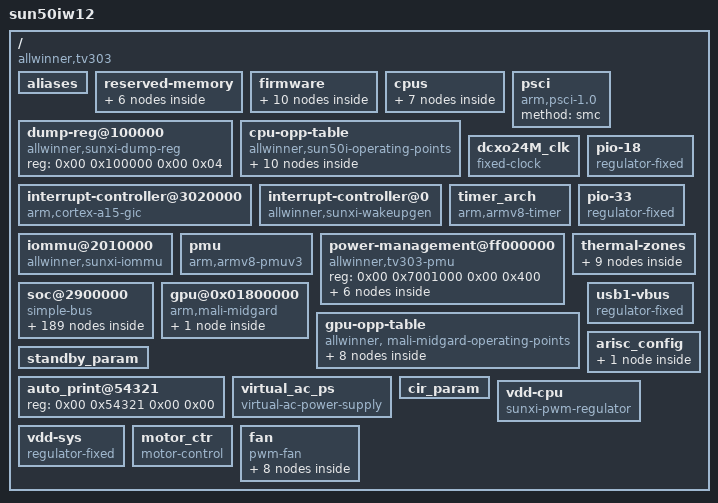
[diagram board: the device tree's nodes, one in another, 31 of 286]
/dts-v1/;

/ {
	interrupt-parent = <0x01>;
	#address-cells = <0x02>;
	#size-cells = <0x02>;
	model = "sun50iw12";
	compatible = "allwinner,tv303\0arm,sun50iw12p1";

	aliases {
		mmc0 = "/soc@2900000/sdmmc@4020000";
		mmc2 = "/soc@2900000/sdmmc@4022000";
		spi0 = "/soc@2900000/spi@4025000";
		spi1 = "/soc@2900000/spi@4026000";
		twi0 = "/soc@2900000/twi@2502000";
		twi1 = "/soc@2900000/twi@2502400";
		twi2 = "/soc@2900000/twi@2502800";
		twi3 = "/soc@2900000/twi@2502C00";
		twi4 = "/soc@2900000/r_twi@7081400";
		twi5 = "/soc@2900000/r_twi@7081800";
		nand0 = "/soc@2900000/nand0@04011000";
		global-timer0 = "/soc@2900000/timer@3060000";
		ir0 = "/soc@2900000/s_cir@7040000";
		ac200 = "/soc@2900000/ac200@0";
		pwm = "/soc@2900000/pwm@2000c00";
		pwm0 = "/soc@2900000/pwm0@2000c10";
		pwm1 = "/soc@2900000/pwm1@2000c11";
		pwm2 = "/soc@2900000/pwm2@2000c12";
		pwm3 = "/soc@2900000/pwm3@2000c13";
		pwm4 = "/soc@2900000/pwm4@2000c14";
		pwm5 = "/soc@2900000/pwm5@2000c15";
		pwm6 = "/soc@2900000/pwm6@2000c16";
		pwm7 = "/soc@2900000/pwm7@2000c17";
		s_pwm = "/soc@2900000/s_pwm@7020c00";
		s_pwm0 = "/soc@2900000/s_pwm0@7020c10";
		s_pwm1 = "/soc@2900000/s_pwm1@7020c11";
		s_pwm2 = "/soc@2900000/s_pwm2@7004012";
		ve0 = "/soc@2900000/ve@1c0e000";
		ve1 = "/soc@2900000/ve1@1c0e000";
		serial0 = "/soc@2900000/uart@2500000";
		serial1 = "/soc@2900000/uart@2500400";
		arisc_config = "/arisc_config";
		standby_param = "/standby_param";
		cir_param = "/cir_param";
	};

	reserved-memory {
		#address-cells = <0x02>;
		#size-cells = <0x02>;
		ranges;

		bl31 {
			reg = <0x00 0x48000000 0x00 0x180000>;
		};

		optee {
			reg = <0x00 0x48600000 0x00 0x100000>;
		};

		mipsloader {
			reg = <0x00 0x4b100000 0x00 0x2841000>;
			phandle = <0x5d>;
		};

		decd {
			reg = <0x00 0x4d941000 0x00 0x20000>;
			phandle = <0x5c>;
		};

		cpu_comm {
			reg = <0x00 0x4e300000 0x00 0x500000>;
			phandle = <0x62>;
		};

		framebuf {
			reg = <0x00 0x4bf41000 0x00 0x1a00000>;
			phandle = <0x63>;
		};
	};

	firmware {

		android {
			compatible = "android,firmware";
			boot_devices = "soc@2900000/4020000.sdmmc,soc@2900000/4022000.sdmmc,soc@2900000";

			vbmeta {
				compatible = "android,vbmeta";
				parts = "vbmeta,vbmeta_system,vbmeta_vendor,boot";
			};
		};

		optee {
			compatible = "linaro,optee-tz";
			method = "smc";
		};

		mips {

			mips_code {
				file_name = "display.bin";
				cert_name = "display.der";
				load_addr = <0x4b100000>;
			};

			mips_database {
				file_name = "database.TSE";
				cert_name = "database.der";
				load_addr = <0x4ba00000>;
			};

			mips_project_table {
				file_name = "projecttable.TSE";
				cert_name = "projecttable.der";
			};

			mips_db_project {
				file_name = "ProjectID_";
			};

			mips_xml {
				file_name = "mips.xml";
				load_addr = <0x4f308000>;
			};

			mips_memory {
				mips_only_size = <0x3200000>;
				shm_size = <0x1018000>;
			};
		};
	};

	cpus {
		#address-cells = <0x02>;
		#size-cells = <0x00>;

		cpu@0 {
			device_type = "cpu";
			compatible = "arm,cortex-a53\0arm,armv8";
			reg = <0x00 0x00>;
			enable-method = "psci";
			clocks = <0x02 0x13>;
			dynamic-power-coefficient = <0xf6>;
			cpu-idle-states = <0x03 0x04>;
			operating-points-v2 = <0x05>;
			#cooling-cells = <0x02>;
			cpu-supply = <0x06>;
			phandle = <0x09>;
		};

		cpu@1 {
			device_type = "cpu";
			compatible = "arm,cortex-a53\0arm,armv8";
			reg = <0x00 0x01>;
			enable-method = "psci";
			clocks = <0x02 0x13>;
			dynamic-power-coefficient = <0xf6>;
			cpu-idle-states = <0x03 0x04>;
			operating-points-v2 = <0x05>;
			#cooling-cells = <0x02>;
			phandle = <0x0a>;
		};

		cpu@2 {
			device_type = "cpu";
			compatible = "arm,cortex-a53\0arm,armv8";
			reg = <0x00 0x02>;
			enable-method = "psci";
			clocks = <0x02 0x13>;
			dynamic-power-coefficient = <0xf6>;
			cpu-idle-states = <0x03 0x04>;
			operating-points-v2 = <0x05>;
			#cooling-cells = <0x02>;
			phandle = <0x0b>;
		};

		cpu@3 {
			device_type = "cpu";
			compatible = "arm,cortex-a53\0arm,armv8";
			reg = <0x00 0x03>;
			enable-method = "psci";
			clocks = <0x02 0x13>;
			dynamic-power-coefficient = <0xf6>;
			cpu-idle-states = <0x03 0x04>;
			operating-points-v2 = <0x05>;
			#cooling-cells = <0x02>;
			phandle = <0x0c>;
		};

		idle-states {
			entry-method = "arm,psci";

			cpu-sleep-0 {
				compatible = "arm,idle-state";
				arm,psci-suspend-param = <0x10000>;
				entry-latency-us = <0x2e>;
				exit-latency-us = <0x3b>;
				min-residency-us = <0xdf2>;
				local-timer-stop;
				phandle = <0x03>;
			};

			cluster-sleep-0 {
				compatible = "arm,idle-state";
				arm,psci-suspend-param = <0x1010000>;
				entry-latency-us = <0x2f>;
				exit-latency-us = <0x4a>;
				min-residency-us = <0x1388>;
				local-timer-stop;
				phandle = <0x04>;
			};
		};
	};

	psci {
		compatible = "arm,psci-1.0";
		method = "smc";
	};

	dump-reg@100000 {
		compatible = "allwinner,sunxi-dump-reg";
		reg = <0x00 0x100000 0x00 0x04>;
		phandle = <0x64>;
	};

	cpu-opp-table {
		compatible = "allwinner,sun50i-operating-points";
		nvmem-cells = <0x07>;
		nvmem-cell-names = "speed";
		opp-shared;
		phandle = <0x05>;

		opp@672000000 {
			opp-hz = <0x00 0x280de800>;
			clock-latency-ns = <0x3b9b0>;
			opp-microvolt = <0xdbba0>;
			opp-microvolt-0x00010042 = <0xdbba0>;
			opp-microvolt-0x00020042 = <0xdbba0>;
			opp-microvolt-0x00040042 = <0xdbba0>;
			opp-microvolt-0x00090042 = <0xdbba0>;
			opp-microvolt-0x000a0042 = <0xdbba0>;
			opp-microvolt-0x000c0042 = <0xdbba0>;
			opp-microvolt-0x00010043 = <0xdbba0>;
			opp-microvolt-0x00020043 = <0xdbba0>;
			opp-microvolt-0x00040043 = <0xdbba0>;
			opp-microvolt-0x00090043 = <0xdbba0>;
			opp-microvolt-0x000a0043 = <0xdbba0>;
			opp-microvolt-0x000c0043 = <0xdbba0>;
			opp-microvolt-0x0002001f = <0xdbba0>;
			opp-microvolt-0x0002002f = <0xdbba0>;
			opp-microvolt-0x000a001f = <0xdbba0>;
			opp-microvolt-0x000a002f = <0xdbba0>;
			opp-microvolt-0x000a0040 = <0xdbba0>;
		};

		opp@792000000 {
			opp-hz = <0x00 0x2f34f600>;
			clock-latency-ns = <0x3b9b0>;
			opp-microvolt = <0xdbba0>;
			opp-microvolt-0x00010042 = <0xdbba0>;
			opp-microvolt-0x00020042 = <0xdbba0>;
			opp-microvolt-0x00040042 = <0xdbba0>;
			opp-microvolt-0x00090042 = <0xdbba0>;
			opp-microvolt-0x000a0042 = <0xdbba0>;
			opp-microvolt-0x000c0042 = <0xdbba0>;
			opp-microvolt-0x00010043 = <0xdbba0>;
			opp-microvolt-0x00020043 = <0xdbba0>;
			opp-microvolt-0x00040043 = <0xdbba0>;
			opp-microvolt-0x00090043 = <0xdbba0>;
			opp-microvolt-0x000a0043 = <0xdbba0>;
			opp-microvolt-0x000c0043 = <0xdbba0>;
			opp-microvolt-0x0002001f = <0xdbba0>;
			opp-microvolt-0x0002002f = <0xdbba0>;
			opp-microvolt-0x000a001f = <0xdbba0>;
			opp-microvolt-0x000a002f = <0xdbba0>;
			opp-microvolt-0x000a0040 = <0xdbba0>;
		};

		opp@1008000000 {
			opp-hz = <0x00 0x3c14dc00>;
			clock-latency-ns = <0x3b9b0>;
			opp-microvolt = <0xe57e0>;
			opp-microvolt-0x00010042 = <0xe57e0>;
			opp-microvolt-0x00020042 = <0xe57e0>;
			opp-microvolt-0x00040042 = <0xe57e0>;
			opp-microvolt-0x00090042 = <0xe57e0>;
			opp-microvolt-0x000a0042 = <0xdbba0>;
			opp-microvolt-0x000c0042 = <0xdbba0>;
			opp-microvolt-0x00010043 = <0xe57e0>;
			opp-microvolt-0x00020043 = <0xe57e0>;
			opp-microvolt-0x00040043 = <0xe57e0>;
			opp-microvolt-0x00090043 = <0xe57e0>;
			opp-microvolt-0x000a0043 = <0xdbba0>;
			opp-microvolt-0x000c0043 = <0xdbba0>;
			opp-microvolt-0x0002001f = <0xdbba0>;
			opp-microvolt-0x0002002f = <0xdbba0>;
			opp-microvolt-0x000a001f = <0xdbba0>;
			opp-microvolt-0x000a002f = <0xdbba0>;
			opp-microvolt-0x000a0040 = <0xdbba0>;
		};

		opp@1104000000 {
			opp-hz = <0x00 0x41cdb400>;
			clock-latency-ns = <0x3b9b0>;
			opp-microvolt = <0x00>;
			opp-microvolt-0x00010042 = <0xea600>;
			opp-microvolt-0x00020042 = <0xea600>;
			opp-microvolt-0x00040042 = <0xea600>;
			opp-microvolt-0x00090042 = <0xea600>;
			opp-microvolt-0x000a0042 = <0xe57e0>;
			opp-microvolt-0x000c0042 = <0xe57e0>;
			opp-microvolt-0x00010043 = <0xea600>;
			opp-microvolt-0x00020043 = <0xea600>;
			opp-microvolt-0x00040043 = <0xea600>;
			opp-microvolt-0x00090043 = <0xea600>;
			opp-microvolt-0x000a0043 = <0xe57e0>;
			opp-microvolt-0x000c0043 = <0xe57e0>;
			opp-microvolt-0x0002001f = <0xe57e0>;
			opp-microvolt-0x0002002f = <0xe57e0>;
			opp-microvolt-0x000a001f = <0xe57e0>;
			opp-microvolt-0x000a002f = <0xe57e0>;
			opp-microvolt-0x000a0040 = <0xe57e0>;
		};

		opp@1200000000 {
			opp-hz = <0x00 0x47868c00>;
			clock-latency-ns = <0x3b9b0>;
			opp-microvolt = <0xf4240>;
			opp-microvolt-0x00010042 = <0xf4240>;
			opp-microvolt-0x00020042 = <0xf4240>;
			opp-microvolt-0x00040042 = <0xf4240>;
			opp-microvolt-0x00090042 = <0xf4240>;
			opp-microvolt-0x000a0042 = <0xea600>;
			opp-microvolt-0x000c0042 = <0xe57e0>;
			opp-microvolt-0x00010043 = <0xf4240>;
			opp-microvolt-0x00020043 = <0xf4240>;
			opp-microvolt-0x00040043 = <0xf4240>;
			opp-microvolt-0x00090043 = <0xf4240>;
			opp-microvolt-0x000a0043 = <0xea600>;
			opp-microvolt-0x000c0043 = <0xe57e0>;
			opp-microvolt-0x0002001f = <0xea600>;
			opp-microvolt-0x0002002f = <0xea600>;
			opp-microvolt-0x000a001f = <0xea600>;
			opp-microvolt-0x000a002f = <0xea600>;
			opp-microvolt-0x000a0040 = <0xea600>;
		};

		opp@1296000000 {
			opp-hz = <0x00 0x4d3f6400>;
			clock-latency-ns = <0x3b9b0>;
			opp-microvolt = <0x102ca0>;
			opp-microvolt-0x00010042 = <0x00>;
			opp-microvolt-0x00020042 = <0x00>;
			opp-microvolt-0x00040042 = <0x00>;
			opp-microvolt-0x00090042 = <0x00>;
			opp-microvolt-0x000a0042 = <0x00>;
			opp-microvolt-0x000c0042 = <0x00>;
			opp-microvolt-0x00010043 = <0x00>;
			opp-microvolt-0x00020043 = <0x00>;
			opp-microvolt-0x00040043 = <0x00>;
			opp-microvolt-0x00090043 = <0x00>;
			opp-microvolt-0x000a0043 = <0x00>;
			opp-microvolt-0x000c0043 = <0x00>;
			opp-microvolt-0x0002001f = <0x00>;
			opp-microvolt-0x0002002f = <0x00>;
			opp-microvolt-0x000a001f = <0x00>;
			opp-microvolt-0x000a002f = <0x00>;
			opp-microvolt-0x000a0040 = <0x00>;
		};

		opp@1320000000 {
			opp-hz = <0x00 0x4ead9a00>;
			clock-latency-ns = <0x3b9b0>;
			opp-microvolt = <0x00>;
			opp-microvolt-0x00010042 = <0x10c8e0>;
			opp-microvolt-0x00020042 = <0x10c8e0>;
			opp-microvolt-0x00040042 = <0x10c8e0>;
			opp-microvolt-0x00090042 = <0x10c8e0>;
			opp-microvolt-0x000a0042 = <0xf4240>;
			opp-microvolt-0x000c0042 = <0xe57e0>;
			opp-microvolt-0x00010043 = <0x10c8e0>;
			opp-microvolt-0x00020043 = <0x10c8e0>;
			opp-microvolt-0x00040043 = <0x10c8e0>;
			opp-microvolt-0x00090043 = <0x10c8e0>;
			opp-microvolt-0x000a0043 = <0xf4240>;
			opp-microvolt-0x000c0043 = <0xe57e0>;
			opp-microvolt-0x0002001f = <0xf4240>;
			opp-microvolt-0x0002002f = <0xf4240>;
			opp-microvolt-0x000a001f = <0xf4240>;
			opp-microvolt-0x000a002f = <0xf4240>;
			opp-microvolt-0x000a0040 = <0xf4240>;
		};

		opp@1392000000 {
			opp-hz = <0x00 0x52f83c00>;
			clock-latency-ns = <0x3b9b0>;
			opp-microvolt = <0x10c8e0>;
			opp-microvolt-0x00010042 = <0x00>;
			opp-microvolt-0x00020042 = <0x00>;
			opp-microvolt-0x00040042 = <0x00>;
			opp-microvolt-0x00090042 = <0x00>;
			opp-microvolt-0x000a0042 = <0x00>;
			opp-microvolt-0x000c0042 = <0x00>;
			opp-microvolt-0x00010043 = <0x00>;
			opp-microvolt-0x00020043 = <0x00>;
			opp-microvolt-0x00040043 = <0x00>;
			opp-microvolt-0x00090043 = <0x00>;
			opp-microvolt-0x000a0043 = <0x00>;
			opp-microvolt-0x000c0043 = <0x00>;
			opp-microvolt-0x0002001f = <0x00>;
			opp-microvolt-0x0002002f = <0x00>;
			opp-microvolt-0x000a001f = <0x00>;
			opp-microvolt-0x000a002f = <0x00>;
			opp-microvolt-0x000a0040 = <0x00>;
		};

		opp@1416000000 {
			opp-hz = <0x00 0x54667200>;
			clock-latency-ns = <0x3b9b0>;
			opp-microvolt = <0x00>;
			opp-microvolt-0x00010042 = <0x00>;
			opp-microvolt-0x00020042 = <0x00>;
			opp-microvolt-0x00040042 = <0x00>;
			opp-microvolt-0x00090042 = <0x00>;
			opp-microvolt-0x000a0042 = <0x00>;
			opp-microvolt-0x000c0042 = <0x00>;
			opp-microvolt-0x00010043 = <0x00>;
			opp-microvolt-0x00020043 = <0x00>;
			opp-microvolt-0x00040043 = <0x00>;
			opp-microvolt-0x00090043 = <0x00>;
			opp-microvolt-0x000a0043 = <0x00>;
			opp-microvolt-0x000c0043 = <0x00>;
			opp-microvolt-0x0002001f = <0x102ca0>;
			opp-microvolt-0x0002002f = <0x102ca0>;
			opp-microvolt-0x000a001f = <0x102ca0>;
			opp-microvolt-0x000a002f = <0x102ca0>;
			opp-microvolt-0x000a0040 = <0x102ca0>;
		};

		opp@1512000000 {
			opp-hz = <0x00 0x5a1f4a00>;
			clock-latency-ns = <0x3b9b0>;
			opp-microvolt = <0x00>;
			opp-microvolt-0x00010042 = <0x00>;
			opp-microvolt-0x00020042 = <0x00>;
			opp-microvolt-0x00040042 = <0x00>;
			opp-microvolt-0x00090042 = <0x00>;
			opp-microvolt-0x000a0042 = <0x00>;
			opp-microvolt-0x000c0042 = <0x00>;
			opp-microvolt-0x00010043 = <0x00>;
			opp-microvolt-0x00020043 = <0x00>;
			opp-microvolt-0x00040043 = <0x00>;
			opp-microvolt-0x00090043 = <0x00>;
			opp-microvolt-0x000a0043 = <0x00>;
			opp-microvolt-0x000c0043 = <0x00>;
			opp-microvolt-0x0002001f = <0x10c8e0>;
			opp-microvolt-0x0002002f = <0x10c8e0>;
			opp-microvolt-0x000a001f = <0x10c8e0>;
			opp-microvolt-0x000a002f = <0x10c8e0>;
			opp-microvolt-0x000a0040 = <0x10c8e0>;
		};
	};

	dcxo24M_clk {
		#clock-cells = <0x00>;
		compatible = "fixed-clock";
		clock-frequency = <0x16e3600>;
		clock-output-names = "dcxo24M";
		phandle = <0x14>;
	};

	interrupt-controller@3020000 {
		compatible = "arm,cortex-a15-gic\0arm,cortex-a9-gic";
		#interrupt-cells = <0x03>;
		#address-cells = <0x00>;
		interrupt-controller;
		reg = <0x00 0x3021000 0x00 0x1000 0x00 0x3022000 0x00 0x2000 0x00 0x3024000 0x00 0x2000 0x00 0x3026000 0x00 0x2000>;
		interrupts = <0x01 0x09 0xf04>;
		interrupt-parent = <0x08>;
		phandle = <0x08>;
	};

	interrupt-controller@0 {
		compatible = "allwinner,sunxi-wakeupgen";
		interrupt-controller;
		#interrupt-cells = <0x03>;
		interrupt-parent = <0x08>;
		phandle = <0x01>;
	};

	timer_arch {
		compatible = "arm,armv8-timer";
		interrupts = <0x01 0x0d 0xf04 0x01 0x0e 0xf04 0x01 0x0b 0xf04 0x01 0x0a 0xf04>;
		clock-frequency = <0x16e3600>;
		interrupt-parent = <0x08>;
		arm,no-tick-in-suspend;
	};

	iommu@2010000 {
		compatible = "allwinner,sunxi-iommu";
		reg = <0x00 0x2010000 0x00 0x1000>;
		interrupts = <0x00 0x47 0x04>;
		interrupt-names = "iommu-irq";
		clocks = <0x02 0x30>;
		clock-names = "iommu";
		#iommu-cells = <0x02>;
		phandle = <0x11>;
	};

	pmu {
		compatible = "arm,armv8-pmuv3";
		interrupts = <0x00 0xac 0x04 0x00 0xad 0x04 0x00 0xae 0x04 0x00 0xaf 0x04>;
		interrupt-affinity = <0x09 0x0a 0x0b 0x0c>;
	};

	power-management@ff000000 {
		compatible = "allwinner,tv303-pmu\0syscon\0simple-mfd";
		reg = <0x00 0x7001000 0x00 0x400>;
		phandle = <0x65>;

		power-controller {
			compatible = "allwinner,tv303-power-controller";
			clocks = <0x0d 0x0f>;
			clock-names = "ppu";
			resets = <0x0d 0x06>;
			reset-names = "ppu_rst";
			#power-domain-cells = <0x01>;
			#address-cells = <0x01>;
			#size-cells = <0x00>;
			phandle = <0x12>;

			pd_gpu@0 {
				reg = <0x00>;
			};

			pd_tvfe@1 {
				reg = <0x01>;
			};

			pd_tvcap@2 {
				reg = <0x02>;
			};

			pd_ve@3 {
				reg = <0x03>;
			};

			pd_av1@4 {
				reg = <0x04>;
			};
		};
	};

	pio-18 {
		compatible = "regulator-fixed";
		regulator-name = "pio-18";
		regulator-min-microvolt = <0x1b7740>;
		regulator-max-microvolt = <0x1b7740>;
		phandle = <0x16>;
	};

	pio-33 {
		compatible = "regulator-fixed";
		regulator-name = "pio-33";
		regulator-min-microvolt = <0x325aa0>;
		regulator-max-microvolt = <0x325aa0>;
		phandle = <0x17>;
	};

	thermal-zones {

		cpu_thermal_zone {
			polling-delay-passive = <0x1f4>;
			polling-delay = <0x3e8>;
			thermal-sensors = <0x0e 0x01>;
			sustainable-power = <0x228>;

			trips {
				phandle = <0x66>;

				trip-point@0 {
					temperature = <0x13880>;
					type = "passive";
					hysteresis = <0x00>;
					phandle = <0x67>;
				};

				trip-point@1 {
					temperature = <0x19a28>;
					type = "passive";
					hysteresis = <0x00>;
					phandle = <0x0f>;
				};

				cpu_crit@0 {
					temperature = <0x1c138>;
					type = "critical";
					hysteresis = <0x00>;
					phandle = <0x68>;
				};
			};

			cooling-maps {

				map0 {
					trip = <0x0f>;
					cooling-device = <0x09 0xffffffff 0xffffffff>;
					contribution = <0x400>;
				};

				map1 {
					trip = <0x0f>;
					cooling-device = <0x10 0xffffffff 0xffffffff>;
					contribution = <0x400>;
				};
			};
		};

		gpu_thermal_zone {
			polling-delay-passive = <0x1f4>;
			polling-delay = <0x3e8>;
			thermal-sensors = <0x0e 0x00>;
			sustainable-power = <0x228>;
		};
	};

	soc@2900000 {
		compatible = "simple-bus";
		#address-cells = <0x02>;
		#size-cells = <0x02>;
		ranges;
		phandle = <0x69>;

		sram_ctrl@3000000 {
			compatible = "allwinner,sram_ctrl";
			reg = <0x00 0x3000000 0x00 0x16c>;
			phandle = <0x6a>;

			soc_ver {
				offset = <0x24>;
				mask = <0x07>;
				shift = <0x00>;
				ver_a = <0x18600000>;
			};

			soc_id {
				offset = <0x200>;
				mask = <0x01>;
				shift = <0x16>;
			};

			soc_bin {
				offset = <0x00>;
				mask = <0x3ff>;
				shift = <0x00>;
			};
		};

		av1@1c0d000 {
			compatible = "allwinner,sunxi-google-ve";
			reg = <0x00 0x1c0d000 0x00 0x1000 0x00 0x2001000 0x00 0x1000>;
			interrupts = <0x00 0x6b 0x04>;
			clocks = <0x02 0x21 0x02 0x22 0x02 0x20 0x02 0x35>;
			clock-names = "bus_ve\0bus_av1\0av1\0mbus_av1";
			resets = <0x02 0x07 0x02 0x08>;
			reset-names = "reset_ve\0reset_av1";
			iommus = <0x11 0x05 0x01>;
			power-domains = <0x12 0x04>;
			phandle = <0x6b>;
		};

		opp_table {
			compatible = "operating-points-v2";
			phandle = <0x13>;

			opp@300000000 {
				opp-hz = <0x00 0x11e1a300>;
			};

			opp@400000000 {
				opp-hz = <0x00 0x17d78400>;
			};

			opp@576000000 {
				opp-hz = <0x00 0x22551000>;
			};

			opp@600000000 {
				opp-hz = <0x00 0x23c34600>;
			};
		};

		ve@1c0e000 {
			compatible = "allwinner,sunxi-cedar-ve";
			reg = <0x00 0x1c0e000 0x00 0x1000 0x00 0x3000000 0x00 0x10>;
			interrupts = <0x00 0x4b 0x04>;
			clocks = <0x02 0x21 0x02 0x23 0x02 0x20 0x02 0x33>;
			clock-names = "bus_ve\0bus_ve3\0ve\0mbus_ve3";
			resets = <0x02 0x07 0x02 0x09>;
			reset-names = "reset_ve\0reset_ve3";
			iommus = <0x11 0x00 0x01>;
			power-domains = <0x12 0x03>;
			operating-points-v2 = <0x13>;
			#cooling-cells = <0x02>;
			phandle = <0x6c>;
		};

		ve1@1c0e000 {
			compatible = "allwinner,sunxi-cedar-ve";
			iommus = <0x11 0x01 0x01>;
			phandle = <0x6d>;
		};

		pinctrl@2000000 {
			compatible = "allwinner,sun50iw12-pinctrl";
			reg = <0x00 0x2000000 0x00 0x400>;
			interrupts = <0x00 0x36 0x04 0x00 0x37 0x04 0x00 0x38 0x04 0x00 0x39 0x04 0x00 0x3a 0x04 0x00 0x3b 0x04 0x00 0x3c 0x04 0x00 0x3d 0x04 0x00 0x3e 0x04>;
			clocks = <0x02 0x17 0x14 0x15 0x03>;
			clock-names = "apb\0hosc\0losc";
			gpio-controller;
			#gpio-cells = <0x03>;
			interrupt-controller;
			#interrupt-cells = <0x03>;
			vcc-pc-supply = <0x16>;
			vcc-pf-supply = <0x16>;
			vcc-pfo-supply = <0x17>;
			phandle = <0x2c>;

			nand0@0 {
				pins = "PC0\0PC1\0PC2\0PC5\0PC8\0PC9\0PC10\0PC11\0PC12\0PC13\0PC14\0PC15\0PC16";
				function = "nand0";
				drive-strength = <0x1e>;
				phandle = <0x53>;
			};

			nand0@1 {
				pins = "PC4\0PC6\0PC3\0PC7";
				function = "nand0";
				drive-strength = <0x1e>;
				bias-pull-up;
				phandle = <0x54>;
			};

			nand0@2 {
				pins = "PC0\0PC1\0PC2\0PC3\0PC4\0PC5\0PC6\0PC7\0PC8\0PC9\0PC10\0PC11\0PC12\0PC13\0PC14\0PC15\0PC16";
				function = "gpio_in";
				phandle = <0x55>;
			};

			sdc0@0 {
				pins = "PF0\0PF1\0PF2\0PF3\0PF4\0PF5";
				function = "mmc0";
				drive-strength = <0x1e>;
				bias-pull-up;
				phandle = <0x4d>;
			};

			sdc0@1 {
				pins = "PF0\0PF1\0PF2\0PF3\0PF4\0PF5";
				function = "mmc0";
				drive-strength = <0x1e>;
				bias-pull-up;
				phandle = <0x6e>;
			};

			sdc0@2 {
				pins = "PF0\0PF1\0PF2\0PF3\0PF4\0PF5";
				function = "gpio_in";
				phandle = <0x4e>;
			};

			sdc0@3 {
				pins = "PF2\0PF4";
				function = "uart0";
				drive-strength = <0x1e>;
				bias-pull-up;
				phandle = <0x4f>;
			};

			sdc0@4 {
				pins = "PF0\0PF1\0PF3\0PF5";
				function = "jtag";
				drive-strength = <0x1e>;
				bias-pull-up;
				phandle = <0x50>;
			};

			sdc2@0 {
				pins = "PC1\0PC5\0PC6\0PC8\0PC9\0PC10\0PC11\0PC13\0PC14\0PC15\0PC16";
				function = "mmc2";
				drive-strength = <0x1e>;
				bias-pull-up;
				phandle = <0x4a>;
			};

			sdc2@1 {
				pins = "PC0\0PC1\0PC5\0PC6\0PC8\0PC9\0PC10\0PC11\0PC13\0PC14\0PC15\0PC16";
				function = "gpio_in";
				phandle = <0x4c>;
			};

			sdc2@2 {
				pins = "PC0";
				function = "mmc2";
				drive-strength = <0x1e>;
				bias-pull-down;
				phandle = <0x4b>;
			};

			sdc1@0 {
				pins = "PG0\0PG1\0PG2\0PG3\0PG4\0PG5";
				function = "mmc1c";
				drive-strength = <0x28>;
				bias-pull-up;
				phandle = <0x51>;
			};

			sdc1@1 {
				pins = "PG0\0PG1\0PG2\0PG3\0PG4\0PG5";
				function = "gpio_in";
				phandle = <0x52>;
			};

			uart0@0 {
				pins = "PH0\0PH1";
				function = "uart0";
				drive-strength = <0x0a>;
				bias-pull-up;
				phandle = <0x26>;
			};

			uart0@1 {
				pins = "PH0\0PH1";
				function = "gpio_in";
				phandle = <0x27>;
			};

			uart1@0 {
				pins = "PG6\0PG7\0PG8\0PG9";
				function = "uart1";
				drive-strength = <0x0a>;
				bias-pull-up;
				phandle = <0x28>;
			};

			uart1@1 {
				pins = "PG6\0PG7\0PG8\0PG9";
				function = "gpio_in";
				phandle = <0x29>;
			};

			twi2@0 {
				pins = "PH4\0PH5";
				function = "twi2";
				drive-strength = <0x0a>;
				bias-pull-up;
				phandle = <0x6f>;
			};

			twi2@1 {
				pins = "PH4\0PH5";
				function = "gpio_in";
				phandle = <0x70>;
			};

			twi1@0 {
				pins = "PH2\0PH3";
				function = "twi1";
				drive-strength = <0x0a>;
				bias-pull-up;
				phandle = <0x2a>;
			};

			twi1@1 {
				pins = "PH2\0PH3";
				function = "gpio_in";
				phandle = <0x2b>;
			};

			gmac@0 {
				pins = "PA0\0PA1\0PA2\0PA3\0PA4\0PA5\0PA6\0PA7\0PA8\0PA9";
				function = "emac";
				drive-strength = <0x0a>;
				phandle = <0x5a>;
			};

			gmac@1 {
				pins = "PA0\0PA1\0PA2\0PA3\0PA4\0PA5\0PA6\0PA7\0PA8\0PA9";
				function = "gpio_in";
				phandle = <0x5b>;
			};

			pwm0@0 {
				pins = "PH17";
				function = "pwm0";
				drive-strength = <0x0a>;
				muxsel = <0x03>;
				bias-pull-down;
				phandle = <0x40>;
			};

			pwm0@2 {
				pins = "PH17";
				function = "d_pwm0";
				muxsel = <0x07>;
				drive-strength = <0x0a>;
				bias-pull-down;
				phandle = <0x71>;
			};

			pwm0@1 {
				pins = "PH17";
				muxsel = <0x0f>;
				function = "io_disabled";
				phandle = <0x41>;
			};

			pwm1@0 {
				pins = "PH18";
				function = "pwm1";
				drive-strength = <0x0a>;
				muxsel = <0x03>;
				bias-pull-up;
				phandle = <0x42>;
			};

			pwm1@1 {
				pins = "PH18";
				function = "gpio_in";
				phandle = <0x43>;
			};

			pwm2@0 {
				pins = "PB4";
				function = "pwm2";
				drive-strength = <0x0a>;
				bias-pull-up;
				phandle = <0x44>;
			};

			pwm2@1 {
				pins = "PB4";
				function = "gpio_in";
				phandle = <0x45>;
			};

			pwm3@0 {
				pins = "PB5";
				function = "pwm3";
				drive-strength = <0x0a>;
				muxsel = <0x02>;
				bias-pull-down;
				phandle = <0x46>;
			};

			pwm3@1 {
				pins = "PB5";
				muxsel = <0x0f>;
				function = "io_disabled";
				phandle = <0x47>;
			};

			pwm3@2 {
				pins = "PB5";
				function = "d_pwm3";
				muxsel = <0x07>;
				drive-strength = <0x0a>;
				bias-pull-down;
				phandle = <0x72>;
			};

			pwm4@0 {
				pins = "PA12";
				function = "pwm4";
				drive-strength = <0x0a>;
				bias-pull-up;
				phandle = <0x48>;
			};

			pwm4@1 {
				pins = "PA12";
				function = "gpio_in";
				phandle = <0x49>;
			};

			spi1@0 {
				pins = "PH11\0PH12\0PH13";
				function = "spi1";
				drive-strength = <0x0a>;
				phandle = <0x57>;
			};

			spi1@1 {
				pins = "PH10";
				function = "spi1";
				drive-strength = <0x0a>;
				bias-pull-up;
				phandle = <0x58>;
			};

			spi1@2 {
				pins = "PH10\0PH11\0PH12\0PH13";
				function = "gpio_in";
				drive-strength = <0x0a>;
				phandle = <0x59>;
			};

			mipsloader@0 {
				pins = "PH6\0PH7";
				function = "uart4";
				phandle = <0x73>;
			};

			mipsloader@1 {
				pins = "PD8\0PD9\0PH8\0PH9";
				function = "mips_jtag";
				phandle = <0x74>;
			};

			mipsloader@2 {
				pins = "PD8\0PD9\0PH6\0PH7\0PH8\0PH9";
				function = "gpio_in";
				phandle = <0x75>;
			};

			owa@0 {
				pins = "PH19";
				function = "owa";
				drive-strength = <0x14>;
				bias-disable;
				phandle = <0x76>;
			};

			owa_sleep@0 {
				pins = "PH19";
				function = "gpio_in";
				drive-strength = <0x14>;
				bias-disable;
				phandle = <0x77>;
			};

			daudio2@0 {
				pins = "PH10\0PH11\0PH12\0PH13";
				function = "d_i2s2";
				drive-strength = <0x14>;
				bias-disable;
				phandle = <0x21>;
			};

			daudio2_sleep@0 {
				pins = "PH10\0PH11\0PH12\0PH13";
				function = "gpio_in";
				drive-strength = <0x14>;
				bias-disable;
				phandle = <0x22>;
			};
		};

		clock@2001000 {
			compatible = "allwinner,sun50iw12-ccu";
			reg = <0x00 0x2001000 0x00 0x1000>;
			clocks = <0x14 0x15 0x03 0x15 0x00>;
			clock-names = "hosc\0losc\0iosc";
			#clock-cells = <0x01>;
			#reset-cells = <0x01>;
			phandle = <0x02>;
		};

		audbrg@203042c {
			compatible = "vs,trid-audio-bridge";
			interrupts = <0x00 0x73 0x04 0x00 0x71 0x04>;
			iommus = <0x11 0x06 0x01>;
			status = "okay";
			phandle = <0x78>;
		};

		codec@2030000 {
			#sound-dai-cells = <0x00>;
			compatible = "allwinner,sunxi-internal-codec";
			reg = <0x00 0x2030000 0x00 0x32c 0x00 0x2031000 0x00 0x7c>;
			clocks = <0x02 0x12 0x02 0x6d 0x02 0x5d 0x02 0x5e 0x02 0x5f>;
			clock-names = "pll_audio\0pll_tvfe\0codec_dac\0codec_adc\0codec_bus";
			resets = <0x02 0x2a>;
			playback_cma = <0x80>;
			capture_cma = <0x100>;
			device_type = "codec";
			digital_vol = <0x00>;
			speaker_vol = <0x1a>;
			headphone_vol = <0x00>;
			dacdrc_used = <0x00>;
			adcdrc_used = <0x00>;
			dachpf_used = <0x00>;
			adchpf_used = <0x00>;
			spk_used = <0x01>;
			pa_level = <0x01>;
			pa_msleep_time = <0xa0>;
			gpio-spk = <0x18 0x00 0x02 0x00>;
			dac_swap_en = <0x00>;
			adc_swap_en = <0x00>;
			daudio_master = <0x01>;
			audio_format = <0x03>;
			signal_inversion = <0x01>;
			mclk_div = <0x04>;
			frametype = <0x00>;
			tdm_config = <0x01>;
			pcm_lrck_period = <0x20>;
			slot_width_select = <0x20>;
			status = "okay";
			phandle = <0x1a>;
		};

		dummy_cpudai@203032c {
			compatible = "allwinner,sunxi-dummy-cpudai";
			reg = <0x00 0x203032c 0x00 0x04>;
			tx_fifo_size = <0x80>;
			rx_fifo_size = <0x100>;
			dac_txdata = <0x2030020>;
			adc_txdata = <0x2030040>;
			playback_cma = <0x80>;
			capture_cma = <0x100>;
			device_type = "cpudai";
			dmas = <0x19 0x07 0x19 0x07>;
			dma-names = "tx\0rx";
			status = "okay";
			phandle = <0x1b>;
		};

		sound@2030330 {
			compatible = "allwinner,sunxi-codec-machine";
			reg = <0x00 0x2030330 0x00 0x04>;
			interrupts = <0x00 0x19 0x04>;
			sunxi,audio-codec = <0x1a>;
			sunxi,cpudai-controller = <0x1b>;
			hp_detect_case = <0x00>;
			device_type = "sndcodec";
			jack_enable = <0x00>;
			status = "okay";
			phandle = <0x79>;
		};

		owa@2036000 {
			#sound-dai-cells = <0x00>;
			compatible = "allwinner,sunxi-owa";
			reg = <0x00 0x2036000 0x00 0x58>;
			clocks = <0x02 0x12 0x02 0x58 0x02 0x5b 0x02 0x04 0x02 0x57 0x02 0x6d>;
			resets = <0x02 0x27>;
			interrupts = <0x00 0x17 0x04>;
			pinctrl_used = <0x00>;
			clk_parent = <0x01>;
			playback_cma = <0x200>;
			capture_cma = <0x80>;
			device_type = "owa0";
			dmas = <0x19 0x02 0x19 0x02>;
			dma-names = "tx\0rx";
			pinctrl-names = "default\0sleep";
			status = "disabled";
			phandle = <0x1c>;
		};

		soundowa0@203605c {
			reg = <0x00 0x203605c 0x00 0x04>;
			compatible = "sunxi,simple-audio-card";
			simple-audio-card,name = "sndowa0";
			status = "okay";
			phandle = <0x7a>;

			simple-audio-card,cpu {
				sound-dai = <0x1c>;
			};

			simple-audio-card,codec {
			};
		};

		owa@2037000 {
			#sound-dai-cells = <0x00>;
			compatible = "allwinner,sunxi-owa";
			reg = <0x00 0x2037000 0x00 0x58>;
			clocks = <0x02 0x12 0x02 0x5a 0x02 0x5c 0x02 0x04 0x02 0x59 0x02 0x6d>;
			resets = <0x02 0x28>;
			interrupts = <0x00 0x18 0x04>;
			pinctrl_used = <0x00>;
			clk_parent = <0x01>;
			playback_cma = <0x200>;
			capture_cma = <0x80>;
			device_type = "owa1";
			dmas = <0x19 0x09 0x19 0x09>;
			dma-names = "tx\0rx";
			status = "okay";
			phandle = <0x1d>;
		};

		soundowa1@203705c {
			reg = <0x00 0x203705c 0x00 0x04>;
			compatible = "sunxi,simple-audio-card";
			simple-audio-card,name = "sndowa1";
			status = "okay";
			phandle = <0x7b>;

			simple-audio-card,cpu {
				sound-dai = <0x1d>;
			};

			simple-audio-card,codec {
			};
		};

		daudio@2032000 {
			#sound-dai-cells = <0x00>;
			compatible = "allwinner,sunxi-daudio";
			reg = <0x00 0x2032000 0x00 0x7c>;
			clocks = <0x02 0x12 0x02 0x51 0x02 0x54 0x02 0x6d>;
			resets = <0x02 0x24>;
			pinctrl_used = <0x00>;
			tdm_num = <0x00>;
			clk_parent = <0x01>;
			capture_cma = <0x80>;
			playback_cma = <0x80>;
			device_type = "daudio0";
			dmas = <0x19 0x03 0x19 0x03>;
			dma-names = "tx\0rx";
			mclk_div = <0x01>;
			frametype = <0x00>;
			tdm_config = <0x01>;
			sign_extend = <0x00>;
			tx_data_mode = <0x00>;
			rx_data_mode = <0x00>;
			msb_lsb_first = <0x00>;
			pcm_lrck_period = <0x20>;
			slot_width_select = <0x20>;
			status = "okay";
			phandle = <0x1f>;
		};

		sounddaudio0@203207c {
			reg = <0x00 0x203207c 0x00 0x04>;
			compatible = "sunxi,simple-audio-card";
			simple-audio-card,name = "snddaudio0";
			simple-audio-card,format = "i2s";
			simple-audio-card,frame-master = <0x1e>;
			simple-audio-card,bitclock-master = <0x1e>;
			status = "okay";
			phandle = <0x7c>;

			simple-audio-card,cpu {
				sound-dai = <0x1f>;
			};

			simple-audio-card,codec {
				phandle = <0x1e>;
			};
		};

		daudio@2033000 {
			#sound-dai-cells = <0x00>;
			compatible = "allwinner,sunxi-daudio";
			reg = <0x00 0x2033000 0x00 0x7c>;
			clocks = <0x02 0x12 0x02 0x52 0x02 0x55 0x02 0x6d>;
			resets = <0x02 0x25>;
			pinctrl_used = <0x00>;
			tdm_num = <0x01>;
			clk_parent = <0x01>;
			capture_cma = <0x80>;
			playback_cma = <0x80>;
			device_type = "daudio1";
			dmas = <0x19 0x04 0x19 0x04>;
			dma-names = "tx\0rx";
			mclk_div = <0x01>;
			frametype = <0x00>;
			tdm_config = <0x01>;
			sign_extend = <0x00>;
			tx_data_mode = <0x00>;
			rx_data_mode = <0x00>;
			msb_lsb_first = <0x00>;
			pcm_lrck_period = <0x80>;
			slot_width_select = <0x20>;
			status = "okay";
			phandle = <0x20>;
		};

		sounddaudio0@203307c {
			reg = <0x00 0x203307c 0x00 0x04>;
			compatible = "sunxi,simple-audio-card";
			simple-audio-card,name = "snddaudio1";
			simple-audio-card,format = "i2s";
			status = "okay";
			phandle = <0x7d>;

			simple-audio-card,cpu {
				sound-dai = <0x20>;
			};

			simple-audio-card,codec {
				phandle = <0x7e>;
			};
		};

		daudio@2034000 {
			#sound-dai-cells = <0x00>;
			compatible = "allwinner,sunxi-daudio";
			reg = <0x00 0x2034000 0x00 0x7c>;
			clocks = <0x02 0x12 0x02 0x53 0x02 0x56 0x02 0x6d>;
			resets = <0x02 0x26>;
			pinctrl_used = <0x01>;
			tdm_num = <0x01>;
			clk_parent = <0x01>;
			capture_cma = <0x80>;
			playback_cma = <0x80>;
			device_type = "daudio2";
			dmas = <0x19 0x05 0x19 0x05>;
			dma-names = "tx\0rx";
			pinctrl-names = "default\0sleep";
			pinctrl-0 = <0x21>;
			pinctrl-1 = <0x22>;
			mclk_div = <0x01>;
			frametype = <0x00>;
			tdm_config = <0x01>;
			sign_extend = <0x00>;
			tx_data_mode = <0x00>;
			rx_data_mode = <0x00>;
			msb_lsb_first = <0x00>;
			pcm_lrck_period = <0x80>;
			slot_width_select = <0x20>;
			status = "disabled";
			phandle = <0x23>;
		};

		sounddaudio2@203407c {
			reg = <0x00 0x203407c 0x00 0x04>;
			compatible = "sunxi,simple-audio-card";
			simple-audio-card,name = "snddaudio2";
			simple-audio-card,format = "i2s";
			status = "okay";
			phandle = <0x7f>;

			simple-audio-card,cpu {
				sound-dai = <0x23>;
			};

			simple-audio-card,codec {
				phandle = <0x80>;
			};
		};

		timer@3060000 {
			compatible = "allwinner,sun50i-timer";
			device_type = "soc_timer";
			reg = <0x00 0x3060000 0x00 0xa0 0x00 0x2001000 0x00 0x1000>;
			interrupt-parent = <0x08>;
			interrupts = <0x00 0x30 0x04>;
			sunxi-timers = <0x24 0x25>;
			phandle = <0x81>;
		};

		timer@0 {
			clocks = <0x14 0x02 0x27 0x02 0x2d>;
			clock-names = "parent\0mod\0bus";
			resets = <0x02 0x0d>;
			phandle = <0x24>;
		};

		timer@1 {
			clocks = <0x14 0x02 0x28 0x02 0x2d>;
			clock-names = "parent\0mod\0bus";
			phandle = <0x25>;
		};

		watchdog@2051000 {
			compatible = "allwinner,sun50i-wdt";
			reg = <0x00 0x2051000 0x00 0x20>;
			interrupts = <0x00 0x35 0x04>;
			status = "okay";
			phandle = <0x82>;
		};

		watchdog@2051400 {
			compatible = "allwinner,sun50i-wdt";
			reg = <0x00 0x2051400 0x00 0x20>;
			interrupts = <0x00 0x2b 0x04>;
			status = "disabled";
			phandle = <0x83>;
		};

		uart@2500000 {
			compatible = "allwinner,sun50i-uart";
			device_type = "uart0";
			reg = <0x00 0x2500000 0x00 0x400>;
			interrupts = <0x00 0x00 0x04>;
			sunxi,uart-fifosize = <0x40>;
			clocks = <0x02 0x41>;
			resets = <0x02 0x16>;
			uart0_port = <0x00>;
			uart0_type = <0x02>;
			status = "okay";
			pinctrl-names = "default\0sleep";
			pinctrl-0 = <0x26>;
			pinctrl-1 = <0x27>;
			phandle = <0x84>;
		};

		uart@2500400 {
			compatible = "allwinner,sun50i-uart";
			device_type = "uart1";
			reg = <0x00 0x2500400 0x00 0x800>;
			interrupts = <0x00 0x01 0x04>;
			sunxi,uart-fifosize = <0x40>;
			clocks = <0x02 0x42>;
			resets = <0x02 0x17>;
			uart1_port = <0x01>;
			uart1_type = <0x04>;
			status = "okay";
			pinctrl-names = "default\0sleep";
			pinctrl-0 = <0x28>;
			pinctrl-1 = <0x29>;
			phandle = <0x85>;
		};

		uart@2500c00 {
			compatible = "allwinner,sun50i-uart";
			device_type = "uart3";
			reg = <0x00 0x2500c00 0x00 0x1000>;
			interrupts = <0x00 0x03 0x04>;
			sunxi,uart-fifosize = <0x40>;
			clocks = <0x02 0x44>;
			resets = <0x02 0x19>;
			uart3_port = <0x03>;
			uart3_type = <0x04>;
			status = "disabled";
			phandle = <0x86>;
		};

		twi@2502000 {
			#address-cells = <0x01>;
			#size-cells = <0x00>;
			compatible = "allwinner,sun50i-twi";
			device_type = "twi0";
			reg = <0x00 0x2502000 0x00 0x400>;
			interrupts = <0x00 0x07 0x04>;
			clocks = <0x02 0x45>;
			resets = <0x02 0x1b>;
			clock-names = "bus";
			status = "disabled";
			phandle = <0x87>;
		};

		twi@2502400 {
			#address-cells = <0x01>;
			#size-cells = <0x00>;
			compatible = "allwinner,sun50i-twi";
			device_type = "twi1";
			reg = <0x00 0x2502400 0x00 0x400>;
			interrupts = <0x00 0x08 0x04>;
			clocks = <0x02 0x46>;
			resets = <0x02 0x1c>;
			clock-names = "bus";
			status = "okay";
			clock-frequency = <0x186a0>;
			pinctrl-0 = <0x2a>;
			pinctrl-1 = <0x2b>;
			pinctrl-names = "default\0sleep";
			twi_drv_used = <0x00>;
			dmas = <0x19 0x2d 0x19 0x2d>;
			dma-names = "tx\0rx";
			phandle = <0x88>;

			lsm6dsr@1_6A {
				compatible = "lsm6dsr";
				reg = <0x6a>;
				status = "okay";
			};

			stk8ba58@18 {
				compatible = "stk,stk83xx";
				reg = <0x18>;
				stk,direction = <0x02>;
				stk,swipe_xy = <0x00>;
				stk,prj_pianzhou = <0x01>;
				stk83xx,irq-gpio = <0x2c 0x01 0x00 0x01>;
				status = "okay";
			};

			kxttj3@18 {
				compatible = "kxtj3";
				reg = <0x0e>;
				kxt,direction = <0x02>;
				kxt,swipe_xy = <0x00>;
				irq-gpio = <0x2c 0x01 0x00 0x01>;
				status = "okay";
			};
		};

		twi@2502800 {
			#address-cells = <0x01>;
			#size-cells = <0x00>;
			compatible = "allwinner,sun50i-twi";
			device_type = "twi2";
			reg = <0x00 0x2502800 0x00 0x400>;
			interrupts = <0x00 0x09 0x04>;
			clocks = <0x02 0x47>;
			resets = <0x02 0x1d>;
			clock-names = "bus";
			status = "disabled";
			phandle = <0x89>;
		};

		twi@2502C00 {
			#address-cells = <0x01>;
			#size-cells = <0x00>;
			compatible = "allwinner,sun50i-twi";
			device_type = "twi3";
			reg = <0x00 0x2502c00 0x00 0x400>;
			interrupts = <0x00 0x0a 0x04>;
			clocks = <0x02 0x48>;
			resets = <0x02 0x1e>;
			clock-names = "bus";
			status = "disabled";
			phandle = <0x8a>;
		};

		r_twi@7081400 {
			#address-cells = <0x01>;
			#size-cells = <0x00>;
			compatible = "allwinner,sun50i-twi";
			device_type = "r_twi0";
			reg = <0x00 0x7081400 0x00 0x400>;
			interrupts = <0x00 0x99 0x04>;
			clocks = <0x0d 0x0d>;
			resets = <0x0d 0x04>;
			clock-names = "bus";
			status = "disabled";
			phandle = <0x8b>;
		};

		r_twi@7081800 {
			#address-cells = <0x01>;
			#size-cells = <0x00>;
			compatible = "allwinner,sun50i-twi";
			device_type = "r_twi1";
			reg = <0x00 0x7081800 0x00 0x400>;
			interrupts = <0x00 0x9a 0x04>;
			clocks = <0x0d 0x0e>;
			resets = <0x0d 0x05>;
			clock-names = "bus";
			status = "disabled";
			phandle = <0x8c>;
		};

		dma-controller@3002000 {
			compatible = "allwinner,sun50iw12-dma";
			reg = <0x00 0x3002000 0x00 0x1000>;
			interrupts = <0x00 0x2d 0x04>;
			clocks = <0x02 0x24 0x02 0x32 0x02 0x7d>;
			clock-names = "bus\0mbus\0vincap";
			dma-channels = <0x10>;
			dma-requests = <0x36>;
			resets = <0x02 0x0a>;
			#dma-cells = <0x01>;
			phandle = <0x19>;
		};

		msgbox@3003000 {
			compatible = "sunxi,msgbox-amp";
			reg = <0x00 0x3003000 0x00 0x400 0x00 0x3003400 0x00 0x400 0x00 0x3003800 0x00 0x400>;
			interrupts = <0x00 0x2e 0x04 0x00 0x6d 0x04 0x00 0x6c 0x04>;
			clocks = <0x02 0x25>;
			rpmsg_id = "sunxi,mips-msgbox\0sunxi,cpus-msgbox";
			resets = <0x02 0x0b>;
			reset-names = "rst";
			msgbox_amp_counts = <0x03>;
			msgbox_amp_local = <0x00>;
			rpmsg_amp_remote-0 = <0x02>;
			rpmsg_read_channel-0 = <0x01>;
			rpmsg_write_channel-0 = <0x01>;
			rpmsg_amp_remote-1 = <0x01>;
			rpmsg_read_channel-1 = <0x01>;
			rpmsg_write_channel-1 = <0x01>;
			phandle = <0x8d>;
		};

		interrupt-controller@7010320 {
			compatible = "allwinner,sun8i-nmi";
			interrupt-controller;
			#interrupt-cells = <0x02>;
			reg = <0x00 0x7010320 0x00 0x0c>;
			interrupts = <0x00 0xac 0x04>;
			pad-control-v1 = <0x7000208>;
			phandle = <0x8e>;
		};

		s_cir@7040000 {
			compatible = "allwinner,s_cir";
			reg = <0x00 0x7040000 0x00 0x400>;
			interrupts = <0x00 0x9b 0x04>;
			interrupt-parent = <0x08>;
			clocks = <0x0d 0x13 0x14 0x0d 0x12>;
			clock-names = "bus\0pclk\0mclk";
			resets = <0x0d 0x07>;
			wakeup-source;
			supply = [00];
			supply_vol = [00];
			status = "okay";
			pinctrl-names = "default\0sleep";
			pinctrl-0 = <0x2d>;
			pinctrl-1 = <0x2e>;
			phandle = <0x8f>;
		};

		ir_receiver {
			compatible = "allwinner,gpio-ir-receiver";
			status = "disabled";
			phandle = <0x90>;
		};

		pwm@2000c00 {
			#pwm-cells = <0x03>;
			compatible = "allwinner,sunxi-pwm";
			reg = <0x00 0x2000c00 0x00 0x3ff>;
			clocks = <0x02 0x2f>;
			resets = <0x02 0x0f>;
			pwm-number = <0x08>;
			pwm-base = <0x00>;
			sunxi-pwms = <0x2f 0x30 0x31 0x32 0x33 0x34 0x35 0x36>;
			phandle = <0x91>;
		};

		s_pwm@7020c00 {
			#pwm-cells = <0x03>;
			compatible = "allwinner,sunxi-pwm";
			reg = <0x00 0x7020c00 0x00 0x3ff>;
			clocks = <0x0d 0x0b 0x0d 0x0a>;
			resets = <0x0d 0x02>;
			pwm-number = <0x03>;
			pwm-base = <0x10>;
			sunxi-pwms = <0x37 0x38 0x39>;
			phandle = <0x61>;
		};

		s_pwm0@7020c10 {
			compatible = "allwinner,sunxi-pwm0";
			reg_base = <0x7020c00>;
			pinctrl-names = "active\0sleep";
			pinctrl-0 = <0x3a>;
			pinctrl-1 = <0x3b>;
			phandle = <0x37>;
		};

		s_pwm1@7020c11 {
			compatible = "allwinner,sunxi-pwm1";
			reg_base = <0x7020c00>;
			pinctrl-names = "active\0sleep";
			pinctrl-0 = <0x3c>;
			pinctrl-1 = <0x3d>;
			phandle = <0x38>;
		};

		s_pwm2@7004012 {
			compatible = "allwinner,sunxi-pwm2";
			reg_base = <0x7020c00>;
			pinctrl-names = "active\0sleep";
			pinctrl-0 = <0x3e>;
			pinctrl-1 = <0x3f>;
			phandle = <0x39>;
		};

		pwm0@2000c10 {
			compatible = "allwinner,sunxi-pwm0";
			reg = <0x00 0x2000c10 0x00 0x04>;
			reg_base = <0x2000c00>;
			pinctrl-names = "active\0sleep";
			pinctrl-0 = <0x40>;
			pinctrl-1 = <0x41>;
			status = "disabled";
			phandle = <0x2f>;
		};

		pwm1@2000c11 {
			compatible = "allwinner,sunxi-pwm1";
			reg = <0x00 0x2000c11 0x00 0x04>;
			reg_base = <0x2000c00>;
			pinctrl-names = "active\0sleep";
			pinctrl-0 = <0x42>;
			pinctrl-1 = <0x43>;
			status = "disabled";
			phandle = <0x30>;
		};

		pwm2@2000c12 {
			compatible = "allwinner,sunxi-pwm2";
			reg = <0x00 0x2000c12 0x00 0x04>;
			reg_base = <0x2000c00>;
			pinctrl-names = "active\0sleep";
			pinctrl-0 = <0x44>;
			pinctrl-1 = <0x45>;
			status = "disabled";
			phandle = <0x31>;
		};

		pwm3@2000c13 {
			compatible = "allwinner,sunxi-pwm3";
			reg = <0x00 0x2000c13 0x00 0x04>;
			reg_base = <0x2000c00>;
			pinctrl-names = "active\0sleep";
			pinctrl-0 = <0x46>;
			pinctrl-1 = <0x47>;
			status = "disabled";
			phandle = <0x32>;
		};

		pwm4@2000c14 {
			compatible = "allwinner,sunxi-pwm4";
			reg = <0x00 0x2000c14 0x00 0x04>;
			reg_base = <0x2000c00>;
			pinctrl-names = "active\0sleep";
			pinctrl-0 = <0x48>;
			pinctrl-1 = <0x49>;
			phandle = <0x33>;
		};

		pwm5@2000c15 {
			compatible = "allwinner,sunxi-pwm5";
			reg = <0x00 0x2000c15 0x00 0x04>;
			reg_base = <0x2000c00>;
			phandle = <0x34>;
		};

		pwm6@2000c16 {
			compatible = "allwinner,sunxi-pwm6";
			reg = <0x00 0x2000c16 0x00 0x04>;
			reg_base = <0x2000c00>;
			phandle = <0x35>;
		};

		pwm7@2000c17 {
			compatible = "allwinner,sunxi-pwm7";
			reg = <0x00 0x2000c17 0x00 0x04>;
			reg_base = <0x2000c00>;
			phandle = <0x36>;
		};

		ac200@0 {
			compatible = "allwinner,sunxi-ac200";
			status = "okay";
			tv_used = <0x01>;
			tv_pwm_ch = <0x04>;
			phandle = <0x92>;
		};

		nsi-controller@2020000 {
			compatible = "allwinner,sun50i-nsi";
			interrupts = <0x00 0x3f 0x04>;
			reg = <0x00 0x2020000 0x00 0x10000>;
			clocks = <0x02 0x04 0x02 0x19 0x02 0x02>;
			clock-names = "pll\0bus\0sdram";
			resets = <0x02 0x00>;
			clock-frequency = <0x17d78400>;
			#nsi-cells = <0x01>;
			phandle = <0x93>;

			cpu {
				mode = <0x00>;
				pri = <0x00>;
				select = <0x00>;
			};

			gpu {
				mode = <0x00>;
				pri = <0x03>;
				select = <0x01>;
			};

			sd1 {
				mode = <0x01>;
				pri = <0x02>;
				select = <0x00>;
			};

			mstg {
				mode = <0x00>;
				pri = <0x01>;
				select = <0x00>;
			};

			ce {
				mode = <0x01>;
				pri = <0x00>;
				select = <0x01>;
			};
		};

		npd@02070000 {
			compatible = "allwinner,sun50i-npd";
			clocks = <0x02 0x16>;
			clock-names = "ahb";
			clock-frequency = <0x8f0d180>;
			status = "okay";
			phandle = <0x94>;
		};

		sid@3006000 {
			compatible = "allwinner,sun50iw12p1-sid\0allwinner,sunxi-sid";
			reg = <0x00 0x3006000 0x00 0x1000>;
			#address-cells = <0x01>;
			#size-cells = <0x01>;

			vf-table@00 {
				reg = <0x00 0x02>;
				phandle = <0x07>;
			};

			calib@14 {
				reg = <0x2c 0x08>;
				phandle = <0x56>;
			};

			secure_status {
				reg = <0x00 0x00>;
				offset = <0xa0>;
				size = <0x04>;
			};

			chipid {
				reg = <0x00 0x00>;
				offset = <0x200>;
				size = <0x10>;
			};

			rotpk {
				reg = <0x00 0x00>;
				offset = <0x270>;
				size = <0x20>;
			};

			ft_zon {
				reg = <0x00 0x00>;
				offset = <0x22c>;
				size = <0x10>;
			};
		};

		hwspinlock@3004000 {
			compatible = "allwinner,sunxi-hwspinlock";
			clocks = <0x02 0x26>;
			clock-names = "clk_hwspinlock_bus";
			resets = <0x02 0x0c>;
			reg = <0x00 0x3004000 0x00 0x1000>;
			num-locks = <0x20>;
			phandle = <0x95>;
		};

		sdmmc@4022000 {
			compatible = "allwinner,sunxi-mmc-v4p6x";
			device_type = "sdc2";
			reg = <0x00 0x4022000 0x00 0x1000>;
			interrupts = <0x00 0x29 0x04>;
			clocks = <0x14 0x02 0x06 0x02 0x8a 0x02 0x3d 0x02 0x40>;
			clock-names = "osc24m\0pll_periph\0pll_periph_800M\0mmc\0ahb";
			resets = <0x02 0x15>;
			reset-names = "rst";
			pinctrl-names = "default\0sleep";
			pinctrl-0 = <0x4a 0x4b>;
			pinctrl-1 = <0x4c>;
			bus-width = <0x08>;
			req-page-count = <0x02>;
			cap-mmc-highspeed;
			cap-cmd23;
			mmc-cache-ctrl;
			non-removable;
			max-frequency = <0x2faf080>;
			cap-erase;
			mmc-high-capacity-erase-size;
			no-sdio;
			no-sd;
			sdc_tm4_sm0_freq0 = <0x00>;
			sdc_tm4_sm0_freq1 = <0x00>;
			sdc_tm4_sm1_freq0 = <0x00>;
			sdc_tm4_sm1_freq1 = <0x00>;
			sdc_tm4_sm2_freq0 = <0x00>;
			sdc_tm4_sm2_freq1 = <0x00>;
			sdc_tm4_sm3_freq0 = <0x5000000>;
			sdc_tm4_sm3_freq1 = <0x05>;
			sdc_tm4_sm4_freq0 = <0x50000>;
			sdc_tm4_sm4_freq1 = <0x04>;
			sdc_tm4_sm4_freq0_cmd = <0x00>;
			sdc_tm4_sm4_freq1_cmd = <0x00>;
			mmc-ddr-1_8v;
			mmc-hs200-1_8v;
			mmc-hs400-1_8v;
			ctl-spec-caps = <0x328>;
			sunxi-power-save-mode;
			sunxi-dis-signal-vol-sw;
			mmc-bootpart-noacc;
			status = "disabled";
			phandle = <0x96>;
		};

		sdmmc@4020000 {
			compatible = "allwinner,sunxi-mmc-v5p3x";
			device_type = "sdc0";
			reg = <0x00 0x4020000 0x00 0x1000>;
			interrupts = <0x00 0x27 0x04>;
			clocks = <0x14 0x02 0x06 0x02 0x3b 0x02 0x3e>;
			clock-names = "osc24m\0pll_periph\0mmc\0ahb";
			resets = <0x02 0x13>;
			reset-names = "rst";
			pinctrl-names = "default\0sleep\0uart_jtag";
			pinctrl-0 = <0x4d>;
			pinctrl-1 = <0x4e>;
			pinctrl-2 = <0x4f 0x50>;
			bus-width = <0x04>;
			cd-used-24M;
			cd-gpios = <0x2c 0x05 0x06 0x11>;
			cap-sd-highspeed;
			no-sdio;
			no-mmc;
			sunxi-power-save-mode;
			max-frequency = <0x2faf080>;
			ctl-spec-caps = <0x08>;
			status = "disabled";
			phandle = <0x97>;
		};

		sdmmc@4021000 {
			compatible = "allwinner,sunxi-mmc-v5p3x";
			device_type = "sdc1";
			reg = <0x00 0x4021000 0x00 0x1000>;
			interrupts = <0x00 0x28 0x04>;
			clocks = <0x14 0x02 0x06 0x02 0x3c 0x02 0x3f>;
			clock-names = "osc24m\0pll_periph\0mmc\0ahb";
			resets = <0x02 0x14>;
			reset-names = "rst";
			pinctrl-names = "default\0sleep";
			pinctrl-0 = <0x51>;
			pinctrl-1 = <0x52>;
			max-frequency = <0x2faf080>;
			bus-width = <0x04>;
			cap-sd-highspeed;
			no-mmc;
			keep-power-in-suspend;
			sunxi-dly-52M-ddr4 = <0x01 0x00 0x00 0x00 0x02>;
			sunxi-dly-104M = <0x01 0x01 0x00 0x00 0x01>;
			sunxi-dly-208M = <0x01 0x00 0x00 0x00 0x01>;
			status = "okay";
			no-sd;
			sd-uhs-sdr25;
			sd-uhs-sdr50;
			sd-uhs-ddr50;
			sd-uhs-sdr104;
			cap-sdio-irq;
			ignore-pm-notify;
			ctl-spec-caps = <0x08>;
			phandle = <0x98>;
		};

		nand0@04011000 {
			compatible = "allwinner,sun50iw12-nand";
			device_type = "nand0";
			reg = <0x00 0x4011000 0x00 0x1000>;
			interrupts = <0x00 0x26 0x04>;
			clocks = <0x02 0x06 0x02 0x38 0x02 0x39 0x02 0x3a 0x02 0x36>;
			clock-names = "pll_periph\0mclk\0ecc\0bus\0mbus";
			resets = <0x02 0x12>;
			reset-names = "rst";
			pinctrl-names = "default\0sleep";
			pinctrl-0 = <0x53 0x54>;
			pinctrl-1 = <0x55>;
			dmas = <0x19 0x0a 0x19 0x0a>;
			dma-names = "tx\0rx";
			nand0_regulator1 = "none";
			nand0_regulator2 = "none";
			nand0_cache_level = <0x55aaaa55>;
			nand0_flush_cache_num = <0x55aaaa55>;
			nand0_capacity_level = <0x55aaaa55>;
			nand0_id_number_ctl = <0x55aaaa55>;
			nand0_print_level = <0x55aaaa55>;
			nand0_p0 = <0x55aaaa55>;
			nand0_p1 = <0x55aaaa55>;
			nand0_p2 = <0x55aaaa55>;
			nand0_p3 = <0x55aaaa55>;
			chip_code = "sun50iw10";
			status = "okay";
			boot_crc = "disabled";
			phandle = <0x99>;
		};

		rtc_ccu@7090000 {
			compatible = "allwinner,sun50iw12-rtc-ccu";
			device_type = "rtc-ccu";
			reg = <0x00 0x7090000 0x00 0x3ff>;
			#clock-cells = <0x01>;
			#reset-cells = <0x01>;
			phandle = <0x15>;
		};

		rtc@7090000 {
			compatible = "allwinner,sun50iw12p1-rtc";
			device_type = "rtc";
			wakeup-source;
			reg = <0x00 0x7090000 0x00 0x3ff>;
			interrupts = <0x00 0x93 0x04>;
			clocks = <0x0d 0x14 0x15 0x06 0x15 0x08>;
			clock-names = "r-ahb-rtc\0rtc-1k\0rtc-spi";
			resets = <0x0d 0x08>;
			gpr_offset = <0x100>;
			gpr_len = <0x08>;
			gpr_cur_pos = <0x06>;
			phandle = <0x9a>;
		};

		clock@7010000 {
			compatible = "allwinner,sun50iw12-r-ccu";
			reg = <0x00 0x7010000 0x00 0x240>;
			clocks = <0x14 0x15 0x03 0x15 0x00 0x02 0x03>;
			clock-names = "hosc\0losc\0iosc\0pll-periph";
			#clock-cells = <0x01>;
			#reset-cells = <0x01>;
			phandle = <0x0d>;
		};

		pinctrl@7022000 {
			compatible = "allwinner,sun50iw12-r-pinctrl";
			reg = <0x00 0x7022000 0x00 0x800>;
			interrupts = <0x00 0x95 0x04 0x00 0x97 0x04>;
			clocks = <0x0d 0x02 0x14 0x15 0x03>;
			clock-names = "apb\0hosc\0losc";
			gpio-controller;
			#gpio-cells = <0x03>;
			interrupt-controller;
			#interrupt-cells = <0x03>;
			phandle = <0x18>;

			s_cir0@0 {
				pins = "PL9";
				function = "s_cir";
				drive-strength = <0x0a>;
				bias-pull-up;
				phandle = <0x2d>;
			};

			s_cir0@1 {
				pins = "PL9";
				function = "gpio_in";
				phandle = <0x2e>;
			};

			s_pwm0@0 {
				pins = "PL6";
				function = "s_pwm0";
				drive-strength = <0x0a>;
				bias-pull-up;
				phandle = <0x3a>;
			};

			s_pwm0@1 {
				pins = "PL6";
				function = "gpio_in";
				phandle = <0x3b>;
			};

			s_pwm1@0 {
				pins = "PL7";
				function = "s_pwm1";
				drive-strength = <0x0a>;
				bias-pull-up;
				phandle = <0x3c>;
			};

			s_pwm1@1 {
				pins = "PL7";
				function = "gpio_in";
				phandle = <0x3d>;
			};

			s_pwm2@0 {
				pins = "PL8";
				function = "s_pwm2";
				drive-strength = <0x0a>;
				bias-pull-up;
				phandle = <0x3e>;
			};

			s_pwm2@1 {
				pins = "PL8";
				function = "gpio_in";
				phandle = <0x3f>;
			};
		};

		ce@03040000 {
			compatible = "allwinner,sunxi-ce";
			device_name = "ce";
			reg = <0x00 0x3040000 0x00 0xa0 0x00 0x3040800 0x00 0xa0>;
			interrupts = <0x00 0x49 0x01 0x00 0x4a 0x01>;
			clock-frequency = <0x17d78400>;
			clocks = <0x02 0x1f 0x02 0x1e 0x02 0x34 0x02 0x04>;
			clock-names = "bus_ce\0ce_clk\0mbus_ce\0pll_periph0_2x";
			resets = <0x02 0x05>;
			status = "okay";
			phandle = <0x9b>;
		};

		ths@02009400 {
			compatible = "allwinner,sun50iw12p1-ths";
			reg = <0x00 0x2009400 0x00 0x400>;
			clocks = <0x02 0x50>;
			clock-names = "bus";
			resets = <0x02 0x23>;
			nvmem-cells = <0x56>;
			nvmem-cell-names = "calibration";
			#thermal-sensor-cells = <0x01>;
			phandle = <0x0e>;
		};

		keyboard@2009800 {
			compatible = "allwinner,keyboard_1350mv";
			reg = <0x00 0x2009800 0x00 0x400>;
			interrupts = <0x00 0x16 0x01>;
			clocks = <0x02 0x6a>;
			clock-names = "bus";
			resets = <0x02 0x35>;
			key_cnt = <0x00>;
			key0 = <0x72 0x7f>;
			key1 = <0xea 0x193>;
			key2 = <0x168 0x192>;
			key3 = <0x1ef 0x71>;
			key4 = <0x26f 0x73>;
			key5 = <0x2eb 0x72>;
			key6 = <0x363 0xac>;
			power-key = <0x74>;
			power-gpio = <0x18 0x00 0x04 0x00>;
			wakeup-source;
			#io-channel-cells = <0x01>;
			status = "okay";
			phandle = <0x9c>;
		};

		gpadc@2009000 {
			compatible = "allwinner,sunxi-gpadc";
			reg = <0x00 0x2009000 0x00 0x400>;
			interrupts = <0x00 0x14 0x01>;
			clocks = <0x02 0x4f>;
			clock-names = "bus";
			resets = <0x02 0x22>;
			status = "okay";
			channel_num = <0x02>;
			channel_select = <0x02>;
			channel_data_select = <0x02>;
			phandle = <0x9d>;
		};

		spi@4025000 {
			#address-cells = <0x01>;
			#size-cells = <0x00>;
			compatible = "allwinner,sun50i-spi";
			device_type = "spi0";
			reg = <0x00 0x4025000 0x00 0x1000>;
			interrupts = <0x00 0x0d 0x04>;
			clocks = <0x02 0x03 0x02 0x49 0x02 0x4b>;
			clock-names = "pll\0mod\0bus";
			resets = <0x02 0x1f>;
			clock-frequency = <0x5f5e100>;
			pinctrl-names = "default\0sleep";
			spi0_cs_number = <0x01>;
			spi0_cs_bitmap = <0x01>;
			dmas = <0x19 0x16 0x19 0x16>;
			dma-names = "tx\0rx";
			status = "disabled";
			phandle = <0x9e>;
		};

		spi@4026000 {
			#address-cells = <0x01>;
			#size-cells = <0x00>;
			compatible = "allwinner,sun50i-spi";
			device_type = "spi1";
			reg = <0x00 0x4026000 0x00 0x1000>;
			interrupts = <0x00 0x0e 0x04>;
			clocks = <0x02 0x03 0x02 0x4a 0x02 0x4c>;
			clock-names = "pll\0mod\0bus";
			resets = <0x02 0x20>;
			clock-frequency = <0x5f5e100>;
			pinctrl-names = "default\0sleep";
			spi1_cs_number = <0x01>;
			spi1_cs_bitmap = <0x01>;
			dmas = <0x19 0x17 0x19 0x17>;
			dma-names = "tx\0rx";
			status = "disabled";
			pinctrl-0 = <0x57 0x58>;
			pinctrl-1 = <0x59>;
			spi_slave_mode = <0x00>;
			phandle = <0x9f>;

			spi_board1@0 {
				device_type = "spi_board1";
				compatible = "rohm,dh2228fv";
				spi-max-frequency = <0x5f5e100>;
				reg = <0x00>;
				spi-rx-bus-width = <0x04>;
				spi-tx-bus-width = <0x04>;
				status = "disabled";
			};
		};

		eth@4500000 {
			compatible = "allwinner,sunxi-gmac";
			reg = <0x00 0x4500000 0x00 0x10000 0x00 0x3000030 0x00 0x04>;
			interrupts = <0x00 0x10 0x04>;
			interrupt-names = "gmacirq";
			clocks = <0x02 0x4e 0x02 0x4d>;
			clock-names = "gmac\0ephy";
			resets = <0x02 0x21>;
			device_type = "gmac0";
			gmac-power0;
			gmac-power1;
			gmac-power2;
			status = "disabled";
			pinctrl-0 = <0x5a>;
			pinctrl-1 = <0x5b>;
			pinctrl-names = "default\0sleep";
			phy-mode = "rmii";
			tx-delay = <0x07>;
			rx-delay = <0x1f>;
			phy-rst;
			phandle = <0xa0>;
		};

		demux@6100000 {
			compatible = "trix,demux";
			reg = <0x00 0x6100000 0x00 0x20000>;
			interrupts = <0x00 0x58 0x01 0x00 0x59 0x01 0x00 0x5b 0x01 0x00 0x5c 0x01>;
			iommus = <0x11 0x06 0x01>;
			phandle = <0xa1>;
		};

		cip@6000000 {
			compatible = "trix,cip";
			reg = <0x00 0x6000000 0x00 0x20000>;
			interrupts = <0x00 0x4e 0x01 0x00 0x52 0x01 0x00 0x53 0x01>;
			phandle = <0xa2>;
		};

		ci@6500000 {
			compatible = "trix,ci";
			reg = <0x00 0x6500000 0x00 0x1000>;
			interrupts = <0x00 0x69 0x01>;
			phandle = <0xa3>;
		};

		ge2d@5240000 {
			compatible = "trix,ge2d";
			reg = <0x00 0x5240000 0x00 0x60000 0x00 0x51c0000 0x00 0x10000 0x00 0x5200000 0x00 0x1000 0x00 0x5600000 0x00 0x1000>;
			interrupts = <0x00 0x65 0x01 0x00 0x67 0x01 0x00 0x68 0x01 0x00 0x70 0x01>;
			clocks = <0x02 0x85 0x02 0x86>;
			clock-names = "clk_afbd\0clk_bus_disp";
			resets = <0x02 0x39>;
			reset-names = "rst_bus_disp";
			iommus = <0x11 0x02 0x00>;
			phandle = <0xa4>;
		};

		io-memory {
			compatible = "trix,io-accessor";
			#address-cells = <0x02>;
			#size-cells = <0x02>;
			ranges;

			io-space-s {
				secure-io;
			};

			io-space-n {
				reg = <0x00 0x6000000 0x00 0x20000 0x00 0x6100000 0x00 0x20000 0x00 0x6144000 0x00 0x1000 0x00 0x6500000 0x00 0x1000 0x00 0x5240000 0x00 0x10000 0x00 0x51c0000 0x00 0x10000 0x00 0x5200000 0x00 0x1000 0x00 0x5600000 0x00 0x1000>;
			};
		};

		cpu_comm {
			compatible = "trix,cpu_comm";
		};

		dtmb@6600000 {
			compatible = "allwinner,sunxi-dtmbip";
			reg = <0x00 0x6600000 0x00 0x4000 0x00 0x6700000 0x00 0x500>;
			clocks = <0x02 0x6c 0x02 0x6b>;
			clock-names = "dtmb_120m\0adc";
			iommus = <0x11 0x06 0x01>;
			status = "okay";
			phandle = <0xa5>;
		};

		dec@5600000 {
			#address-cells = <0x02>;
			#size-cells = <0x02>;
			ranges;
			compatible = "allwinner,sunxi-dec\0simple-bus";
			reg = <0x00 0x5700000 0x00 0x100 0x00 0x5600000 0x00 0x400>;
			interrupts = <0x00 0x6e 0x04>;
			clocks = <0x02 0x85 0x02 0x86>;
			clock-names = "clk_afbd\0clk_bus_disp";
			resets = <0x02 0x39>;
			reset-names = "rst_bus_disp";
			clock-frequency = <0xbebc200>;
			iommus = <0x11 0x02 0x00>;
			memory-region = <0x5c>;
			phandle = <0xa6>;

			mipsloader@3061000 {
				#address-cells = <0x02>;
				#size-cells = <0x02>;
				compatible = "allwinner,sunxi-mipsloader";
				reg = <0x00 0x3061000 0x00 0x100>;
				resets = <0x02 0x01 0x02 0x02 0x02 0x03>;
				reset-names = "bus-reset\0cold-reset\0soft-reset";
				clocks = <0x02 0x1b 0x02 0x1a>;
				clock-names = "bus-clk\0mips-clk";
				memory-region = <0x5d>;
				status = "okay";
				phandle = <0xa7>;
			};
		};

		tvcap@6800000 {
			compatible = "allwinner,sunxi-tvsystem-iommu-dev";
			iommus = <0x11 0x04 0x01>;
			phandle = <0xa8>;
		};

		tvdisp@5000000 {
			compatible = "allwinner,sunxi-tvsystem-iommu-dev";
			iommus = <0x11 0x03 0x01>;
			phandle = <0xa9>;
		};

		tvtop@5700000 {
			compatible = "allwinner,sunxi-tvtop";
			reg = <0x00 0x5700000 0x00 0x100 0x00 0x6e00000 0x00 0x100 0x00 0x6700000 0x00 0x100>;
			resets = <0x02 0x39 0x02 0x38 0x02 0x37>;
			reset-names = "reset_bus_disp\0reset_bus_tvcap\0reset_bus_demod";
			assigned-clocks = <0x02 0x84 0x02 0x82 0x02 0x83 0x02 0x71 0x02 0x6f 0x02 0x70 0x02 0x72 0x02 0x78 0x02 0x77 0x02 0x6e 0x02 0x74 0x02 0x73 0x02 0x6b 0x02 0x6d 0x02 0x75 0x02 0x76 0x02 0x79 0x02 0x7a 0x02 0x6c 0x02 0x7c 0x02 0x7d 0x02 0x80>;
			assigned-clock-parents = <0x02 0x04 0x02 0x0d 0x02 0x0d 0x02 0x09 0x02 0x03 0x02 0x03 0x02 0x09 0x02 0x09 0x02 0x03 0x02 0x04 0x02 0x0b 0x02 0x08 0x02 0x0f 0x02 0x09 0x02 0x04 0x02 0x03 0x02 0x0b 0x02 0x0b 0x02 0x0f 0x02 0x09 0x02 0x03 0x02 0x11>;
			clocks = <0x02 0x86 0x02 0x81 0x02 0x7b 0x02 0x84 0x02 0x82 0x02 0x83 0x02 0x71 0x02 0x6f 0x02 0x70 0x02 0x72 0x02 0x78 0x02 0x77 0x02 0x6e 0x02 0x74 0x02 0x73 0x02 0x6d 0x02 0x75 0x02 0x76 0x02 0x79 0x02 0x7a 0x02 0x6b 0x02 0x6c 0x02 0x7f 0x02 0x7e 0x02 0x7c 0x02 0x7d 0x02 0x80>;
			clock-names = "clk_bus_disp\0clk_bus_tvcap\0clk_bus_demod\0svp_dtl_clk\0deint_clk\0panel_clk\0cip_tsp_clk\0cip_tsx_clk\0cip_mcx_clk\0tsa_tsp_clk\0tsa432_clk\0audio_ihb_clk\0i2h_clk\0cip_mts0_clk\0cip27_clk\0tvfe_1296M_clk\0audio_cpu\0audio_umac\0mpg0\0mpg1\0adc\0dtmb-120M\0cap_300m\0hdmi_audio_bus\0tcd3_clk\0vincap_dma_clk\0hdmi_audio_clk";
			panel_power_en = <0x2c 0x05 0x06 0x20>;
			panel_bl_en = <0x2c 0x01 0x05 0x00>;
			panel_gpio_0 = <0x2c 0x07 0x10 0x20>;
			lcd_standby = <0x2c 0x07 0x0f 0x01 0x02 0x03 0x01>;
			spi_cs = <0x2c 0x07 0x0a 0x01 0x02 0x03 0x01>;
			spi_scl = <0x2c 0x07 0x0b 0x01 0x02 0x03 0x01>;
			spi_sda = <0x2c 0x07 0x0c 0x01 0x02 0x03 0x01>;
			panel_pwm_ch = <0x02>;
			panel_pwm_freq = <0x61a8>;
			panel_pwm_pol = <0x00>;
			panel_backlight = <0x4b>;
			panel_pwm_min = <0x00>;
			panel_pwm_max = <0x64>;
			panel_protocol = <0x00>;
			panel_bitwidth = <0x08>;
			panel_data_swap = <0x00>;
			panel_mirror_mode = <0x00>;
			panel_dclk_invert = <0x01>;
			panel_de_invert = <0x00>;
			panel_hs_invert = <0x00>;
			panel_vs_invert = <0x00>;
			panel_dual_port = <0x01>;
			panel_odd_data_current = <0x07>;
			panel_even_data_current = <0x07>;
			panel_de_current = <0x2f>;
			panel_dclk_freq = <0x8d9ee20>;
			panel_ssc_en = <0x01>;
			panel_ssc_step = <0x0a>;
			panel_ssc_span = <0x00>;
			panel_poweron_delay0 = <0x14>;
			panel_poweron_delay1 = <0x226>;
			panel_poweron_delay2 = <0x4b>;
			panel_powerdown_delay0 = <0x14>;
			panel_powerdown_delay1 = <0xfa>;
			panel_powerdown_delay2 = <0x4b>;
			phandle = <0xaa>;
		};

		tvtop_pm@66666 {
			compatible = "allwinner,sunxi-tvtop-pm";
			power-domains = <0x12 0x02 0x12 0x01>;
			power-domain-names = "pd_tvcap\0pd_tvfe";
			phandle = <0xab>;
		};

		usbc0@0 {
			device_type = "usbc0";
			compatible = "allwinner,sunxi-otg-manager";
			usb_port_type = <0x00>;
			usb_detect_type = <0x01>;
			usb_detect_mode = <0x00>;
			usb_id_gpio = "axp_ctrl";
			usb_det_vbus_gpio = "axp_ctrl";
			usb_wakeup_suspend = <0x01>;
			usb_serial_unique = <0x00>;
			usb_serial_number = "20080411";
			rndis_wceis = <0x01>;
			enable-active-high;
			usb_regulator_io = "nocare";
			wakeup-source;
			usb_luns = <0x03>;
			status = "okay";
			phandle = <0xac>;
		};

		udc-controller@4100000 {
			compatible = "allwinner,sunxi-udc";
			reg = <0x00 0x4100000 0x00 0x1000 0x00 0x00 0x00 0x100>;
			interrupts = <0x00 0x20 0x04>;
			clocks = <0x02 0x69>;
			clock-names = "bus_otg";
			resets = <0x02 0x34 0x02 0x2b>;
			reset-names = "otg\0phy";
			status = "okay";
			phandle = <0xad>;
		};

		ehci0-controller@4101000 {
			compatible = "allwinner,sunxi-ehci0";
			reg = <0x00 0x4101000 0x00 0xfff 0x00 0x00 0x00 0x100 0x00 0x4100000 0x00 0x1000>;
			interrupts = <0x00 0x1e 0x04>;
			clocks = <0x02 0x66>;
			clock-names = "bus_hci";
			resets = <0x02 0x31 0x02 0x2b>;
			reset-names = "hci\0phy";
			hci_ctrl_no = <0x00>;
			drvvbus-supply = <0x5e>;
			status = "okay";
			phandle = <0xae>;
		};

		ohci0-controller@4101400 {
			compatible = "allwinner,sunxi-ohci0";
			reg = <0x00 0x4101400 0x00 0xfff 0x00 0x00 0x00 0x100 0x00 0x4100000 0x00 0x1000>;
			interrupts = <0x00 0x1f 0x04>;
			clocks = <0x02 0x63 0x02 0x60>;
			clock-names = "bus_hci\0ohci";
			resets = <0x02 0x2e 0x02 0x2b>;
			reset-names = "hci\0phy";
			hci_ctrl_no = <0x00>;
			drvvbus-supply = <0x5e>;
			status = "okay";
			phandle = <0xaf>;
		};

		usbc1@0 {
			device_type = "usbc1";
			usb_wakeup_suspend = <0x01>;
			usb_regulator_io = "nocare";
			wakeup-source;
			status = "okay";
			phandle = <0xb0>;
		};

		ehci1-controller@4200000 {
			compatible = "allwinner,sunxi-ehci1";
			reg = <0x00 0x4200000 0x00 0xfff 0x00 0x00 0x00 0x100 0x00 0x4100000 0x00 0x1000>;
			interrupts = <0x00 0x21 0x04>;
			clocks = <0x02 0x67>;
			clock-names = "bus_hci";
			resets = <0x02 0x32 0x02 0x2c>;
			reset-names = "hci\0phy";
			hci_ctrl_no = <0x01>;
			drvvbus-supply = <0x5e>;
			status = "okay";
			phandle = <0xb1>;
		};

		ohci1-controller@4200400 {
			compatible = "allwinner,sunxi-ohci1";
			reg = <0x00 0x4200400 0x00 0xfff 0x00 0x00 0x00 0x100 0x00 0x4100000 0x00 0x1000>;
			interrupts = <0x00 0x22 0x04>;
			clocks = <0x02 0x64 0x02 0x61>;
			clock-names = "bus_hci\0ohci";
			resets = <0x02 0x2f 0x02 0x2c>;
			reset-names = "hci\0phy";
			hci_ctrl_no = <0x01>;
			drvvbus-supply = <0x5e>;
			status = "okay";
			phandle = <0xb2>;
		};

		usbc2@0 {
			device_type = "usbc2";
			usb_wakeup_suspend = <0x01>;
			usb_regulator_io = "nocare";
			wakeup-source;
			status = "okay";
			phandle = <0xb3>;
		};

		ehci2-controller@4300000 {
			compatible = "allwinner,sunxi-ehci1";
			reg = <0x00 0x4300000 0x00 0xfff 0x00 0x00 0x00 0x100 0x00 0x4100000 0x00 0x1000>;
			interrupts = <0x00 0x23 0x04>;
			clocks = <0x02 0x68>;
			clock-names = "bus_hci";
			resets = <0x02 0x33 0x02 0x2d>;
			reset-names = "hci\0phy";
			hci_ctrl_no = <0x02>;
			drvvbus-supply = <0x5e>;
			status = "okay";
			phandle = <0xb4>;
		};

		ohci2-controller@4300400 {
			compatible = "allwinner,sunxi-ohci1";
			reg = <0x00 0x4300400 0x00 0xfff 0x00 0x00 0x00 0x100 0x00 0x4100000 0x00 0x1000>;
			interrupts = <0x00 0x24 0x04>;
			clocks = <0x02 0x65 0x02 0x62>;
			clock-names = "bus_hci\0ohci";
			resets = <0x02 0x30 0x02 0x2d>;
			reset-names = "hci\0phy";
			hci_ctrl_no = <0x02>;
			drvvbus-supply = <0x5e>;
			status = "okay";
			phandle = <0xb5>;
		};

		rfkill {
			compatible = "allwinner,sunxi-rfkill";
			status = "okay";
			chip_en;
			power_en;
			pinctrl-0;
			pinctrl-names;
			phandle = <0xb6>;

			wlan {
				compatible = "allwinner,sunxi-wlan";
				clocks = <0x15 0x09>;
				clock-names = "dcxo24m";
				wlan_power;
				wlan_power_vol;
				wlan_busnum = <0x01>;
				wlan_regon = <0x18 0x01 0x01 0x00>;
				wlan_hostwake = <0x18 0x01 0x00 0x00>;
				wakeup-source;
			};

			bt {
				compatible = "allwinner,sunxi-bt";
				clocks = <0x15 0x09>;
				clock-names = "dcxo24m";
				bt_power;
				bt_power_vol;
				bt_rst_n = <0x18 0x01 0x04 0x01>;
			};
		};

		addr_mgt {
			compatible = "allwinner,sunxi-addr_mgt";
			status = "okay";
			type_addr_wifi = <0x00>;
			type_addr_bt = <0x00>;
			type_addr_eth = <0x00>;
			phandle = <0xb7>;
		};

		btlpm {
			compatible = "allwinner,sunxi-btlpm";
			status = "okay";
			device_type = "btlpm";
			uart_index = <0x01>;
			bt_wake = <0x18 0x01 0x02 0x00>;
			bt_hostwake = <0x18 0x01 0x03 0x00>;
			wakeup-source;
			phandle = <0xb8>;
		};

		gpio_para {
			device_type = "gpio_para";
			compatible = "allwinner,sunxi-init-gpio";
			gpio_num = <0x01>;
			gpio_pin_1 = <0x18 0x00 0x01 0x00>;
			status = "disabled";
		};
	};

	gpu@0x01800000 {
		device_type = "gpu";
		compatible = "arm,mali-midgard";
		reg = <0x00 0x1800000 0x00 0x10000>;
		interrupts = <0x00 0x75 0x04 0x00 0x76 0x04 0x00 0x4c 0x04>;
		interrupt-names = "JOB\0MMU\0GPU";
		clocks = <0x02 0x07 0x02 0x1c 0x02 0x1d>;
		clock-names = "clk_parent\0clk_mali\0clk_bus";
		resets = <0x02 0x04>;
		#cooling-cells = <0x02>;
		power-domains = <0x12 0x00>;
		operating-points-v2 = <0x5f>;
		gpu_idle = <0x01>;
		dvfs_status = <0x00>;
		gpu-supply = <0x60>;
		phandle = <0x10>;

		ipa_dvfs {
			compatible = "arm,mali-simple-power-model";
			static-coefficient = <0x16a8>;
			dynamic-coefficient = <0x35c>;
			ts = <0xf4240 0xffffc310 0xffffffb0 0x09>;
			thermal-zone = "gpu_thermal_zone";
			phandle = <0xb9>;
		};
	};

	gpu-opp-table {
		compatible = "allwinner, mali-midgard-operating-points";
		phandle = <0x5f>;

		opp@150000000 {
			opp-hz = <0x00 0x8f0d180>;
			opp-microvolt = <0x00>;
			opp-microvolt-0x00000042 = <0xea600>;
			opp-microvolt-0x00010042 = <0xea600>;
			opp-microvolt-0x00020042 = <0xea600>;
			opp-microvolt-0x00040042 = <0xea600>;
			opp-microvolt-0x00090042 = <0xea600>;
			opp-microvolt-0x000a0042 = <0xea600>;
			opp-microvolt-0x000c0042 = <0xea600>;
			opp-microvolt-0x00000043 = <0xea600>;
			opp-microvolt-0x00010043 = <0xea600>;
			opp-microvolt-0x00020043 = <0xea600>;
			opp-microvolt-0x00040043 = <0xea600>;
			opp-microvolt-0x00090043 = <0xea600>;
			opp-microvolt-0x000a0043 = <0xea600>;
			opp-microvolt-0x000c0043 = <0xea600>;
			opp-microvolt-0x0000001f = <0xea600>;
			opp-microvolt-0x0000002f = <0xea600>;
			opp-microvolt-0x0002001f = <0x00>;
			opp-microvolt-0x0002002f = <0x00>;
		};

		opp@174000000 {
			opp-hz = <0x00 0xa5f0780>;
			opp-microvolt = <0x00>;
			opp-microvolt-0x00000042 = <0x00>;
			opp-microvolt-0x00010042 = <0x00>;
			opp-microvolt-0x00020042 = <0x00>;
			opp-microvolt-0x00040042 = <0x00>;
			opp-microvolt-0x00000043 = <0x00>;
			opp-microvolt-0x00010043 = <0x00>;
			opp-microvolt-0x00020043 = <0x00>;
			opp-microvolt-0x00040043 = <0x00>;
			opp-microvolt-0x0000001f = <0x00>;
			opp-microvolt-0x0000002f = <0x00>;
			opp-microvolt-0x0002001f = <0xea600>;
			opp-microvolt-0x000a001f = <0xea600>;
			opp-microvolt-0x0002002f = <0xea600>;
			opp-microvolt-0x000a002f = <0xea600>;
			opp-microvolt-0x000a0040 = <0xea600>;
		};

		opp@200000000 {
			opp-hz = <0x00 0xbebc200>;
			opp-microvolt = <0x00>;
			opp-microvolt-0x00000042 = <0xea600>;
			opp-microvolt-0x00010042 = <0xea600>;
			opp-microvolt-0x00020042 = <0xea600>;
			opp-microvolt-0x00040042 = <0xea600>;
			opp-microvolt-0x00090042 = <0xea600>;
			opp-microvolt-0x000a0042 = <0xea600>;
			opp-microvolt-0x000c0042 = <0xea600>;
			opp-microvolt-0x00000043 = <0xea600>;
			opp-microvolt-0x00010043 = <0xea600>;
			opp-microvolt-0x00020043 = <0xea600>;
			opp-microvolt-0x00040043 = <0xea600>;
			opp-microvolt-0x00090043 = <0xea600>;
			opp-microvolt-0x000a0043 = <0xea600>;
			opp-microvolt-0x000c0043 = <0xea600>;
			opp-microvolt-0x0000001f = <0xea600>;
			opp-microvolt-0x0000002f = <0xea600>;
			opp-microvolt-0x0002001f = <0x00>;
			opp-microvolt-0x0002002f = <0x00>;
		};

		opp@232000000 {
			opp-hz = <0x00 0xdd40a00>;
			opp-microvolt = <0x00>;
			opp-microvolt-0x00000042 = <0x00>;
			opp-microvolt-0x00010042 = <0x00>;
			opp-microvolt-0x00020042 = <0x00>;
			opp-microvolt-0x00040042 = <0x00>;
			opp-microvolt-0x00000043 = <0x00>;
			opp-microvolt-0x00010043 = <0x00>;
			opp-microvolt-0x00020043 = <0x00>;
			opp-microvolt-0x00040043 = <0x00>;
			opp-microvolt-0x0000001f = <0x00>;
			opp-microvolt-0x0000002f = <0x00>;
			opp-microvolt-0x0002001f = <0xea600>;
			opp-microvolt-0x000a001f = <0xea600>;
			opp-microvolt-0x0002002f = <0xea600>;
			opp-microvolt-0x000a002f = <0xea600>;
			opp-microvolt-0x000a0040 = <0xea600>;
		};

		opp@300000000 {
			opp-hz = <0x00 0x11e1a300>;
			opp-microvolt = <0x00>;
			opp-microvolt-0x00000042 = <0xea600>;
			opp-microvolt-0x00010042 = <0xea600>;
			opp-microvolt-0x00020042 = <0xea600>;
			opp-microvolt-0x00040042 = <0xea600>;
			opp-microvolt-0x00090042 = <0xea600>;
			opp-microvolt-0x000a0042 = <0xea600>;
			opp-microvolt-0x000c0042 = <0xea600>;
			opp-microvolt-0x00000043 = <0xea600>;
			opp-microvolt-0x00010043 = <0xea600>;
			opp-microvolt-0x00020043 = <0xea600>;
			opp-microvolt-0x00040043 = <0xea600>;
			opp-microvolt-0x00090043 = <0xea600>;
			opp-microvolt-0x000a0043 = <0xea600>;
			opp-microvolt-0x000c0043 = <0xea600>;
			opp-microvolt-0x0000001f = <0xea600>;
			opp-microvolt-0x0000002f = <0xea600>;
			opp-microvolt-0x0002001f = <0x00>;
			opp-microvolt-0x0002002f = <0x00>;
		};

		opp@348000000 {
			opp-hz = <0x00 0x14be0f00>;
			opp-microvolt = <0x00>;
			opp-microvolt-0x00000042 = <0x00>;
			opp-microvolt-0x00010042 = <0x00>;
			opp-microvolt-0x00020042 = <0x00>;
			opp-microvolt-0x00040042 = <0x00>;
			opp-microvolt-0x00000043 = <0x00>;
			opp-microvolt-0x00010043 = <0x00>;
			opp-microvolt-0x00020043 = <0x00>;
			opp-microvolt-0x00040043 = <0x00>;
			opp-microvolt-0x0000001f = <0x00>;
			opp-microvolt-0x0000002f = <0x00>;
			opp-microvolt-0x0002001f = <0xea600>;
			opp-microvolt-0x000a001f = <0xea600>;
			opp-microvolt-0x0002002f = <0xea600>;
			opp-microvolt-0x000a002f = <0xea600>;
			opp-microvolt-0x000a0040 = <0xea600>;
		};

		opp@600000000 {
			opp-hz = <0x00 0x23c34600>;
			opp-microvolt = <0xea600>;
			opp-microvolt-0x00000042 = <0xea600>;
			opp-microvolt-0x00010042 = <0xea600>;
			opp-microvolt-0x00020042 = <0xea600>;
			opp-microvolt-0x00040042 = <0xea600>;
			opp-microvolt-0x00090042 = <0xea600>;
			opp-microvolt-0x000a0042 = <0xea600>;
			opp-microvolt-0x000c0042 = <0xea600>;
			opp-microvolt-0x00000043 = <0xea600>;
			opp-microvolt-0x00010043 = <0xea600>;
			opp-microvolt-0x00020043 = <0xea600>;
			opp-microvolt-0x00040043 = <0xea600>;
			opp-microvolt-0x00090043 = <0xea600>;
			opp-microvolt-0x000a0043 = <0xea600>;
			opp-microvolt-0x000c0043 = <0xea600>;
			opp-microvolt-0x0000001f = <0xea600>;
			opp-microvolt-0x0000002f = <0xea600>;
			opp-microvolt-0x0002001f = <0x00>;
			opp-microvolt-0x000a001f = <0x00>;
			opp-microvolt-0x0002002f = <0x00>;
			opp-microvolt-0x000a002f = <0x00>;
			opp-microvolt-0x000a0040 = <0x00>;
		};

		opp@700000000 {
			opp-hz = <0x00 0x29b92700>;
			opp-microvolt = <0x00>;
			opp-microvolt-0x00000042 = <0x00>;
			opp-microvolt-0x00010042 = <0x00>;
			opp-microvolt-0x00020042 = <0x00>;
			opp-microvolt-0x00040042 = <0x00>;
			opp-microvolt-0x00000043 = <0x00>;
			opp-microvolt-0x00010043 = <0x00>;
			opp-microvolt-0x00020043 = <0x00>;
			opp-microvolt-0x00040043 = <0x00>;
			opp-microvolt-0x0000001f = <0x00>;
			opp-microvolt-0x0000002f = <0x00>;
			opp-microvolt-0x0002001f = <0xea600>;
			opp-microvolt-0x000a001f = <0xea600>;
			opp-microvolt-0x0002002f = <0xea600>;
			opp-microvolt-0x000a002f = <0xea600>;
			opp-microvolt-0x000a0040 = <0xea600>;
		};
	};

	usb1-vbus {
		compatible = "regulator-fixed";
		gpio = <0x18 0x00 0x03 0x00>;
		regulator-name = "usb1-vbus";
		regulator-min-microvolt = <0x4c4b40>;
		regulator-max-microvolt = <0x4c4b40>;
		regulator-enable-ramp-delay = <0x3e8>;
		enable-active-high;
		regulator-always-on;
		regulator-boot-on;
		status = "okay";
		phandle = <0x5e>;
	};

	arisc_config {
		phandle = <0xba>;

		s_uart_config {
			pins = "PL10\0PL11";
			function = <0x03 0x03>;
			status = "disabled";
		};
	};

	standby_param {
		power_key = "PL4";
		vdd-cpu = "PL6";
		vdd-sys = "PL6";
		vcc-pll = "PL6";
		vcc-dram = "PL6";
		led_red = "PL0";
		led_blue = "PL1";
		power_down = <0x00>;
		key_debounce = <0x32>;
		phandle = <0xbb>;
	};

	auto_print@54321 {
		reg = <0x00 0x54321 0x00 0x00>;
		device_type = "auto_print";
		status = "okay";
	};

	virtual_ac_ps {
		compatible = "virtual-ac-power-supply";
		phandle = <0xbc>;
	};

	cir_param {
		gpio_group = "PL";
		gpio_pin = <0x09>;
		gpio_function = <0x03>;
		count = <0x13>;
		ir_power_key_code0 = <0x14>;
		ir_addr_code0 = <0xff00>;
		ir_power_key_code1 = <0x45>;
		ir_addr_code1 = <0xff00>;
		ir_power_key_code2 = <0xf2>;
		ir_addr_code2 = <0x2992>;
		ir_power_key_code3 = <0x57>;
		ir_addr_code3 = <0x9f00>;
		ir_power_key_code4 = <0xdc>;
		ir_addr_code4 = <0x4cb3>;
		ir_power_key_code5 = <0x18>;
		ir_addr_code5 = <0xff11>;
		ir_power_key_code6 = <0xdc>;
		ir_addr_code6 = <0xdd22>;
		ir_power_key_code7 = <0x0d>;
		ir_addr_code7 = <0xbc00>;
		ir_power_key_code8 = <0x4d>;
		ir_addr_code8 = <0x4040>;
		ir_power_key_code9 = <0x08>;
		ir_addr_code9 = <0xfb04>;
		ir_power_key_code10 = <0x00>;
		ir_addr_code10 = <0xfc03>;
		ir_power_key_code11 = <0x00>;
		ir_addr_code11 = <0xbf00>;
		ir_power_key_code12 = <0xea>;
		ir_addr_code12 = <0xfb04>;
		ir_power_key_code13 = <0x42>;
		ir_addr_code13 = <0xbf00>;
		ir_power_key_code14 = <0xeb>;
		ir_addr_code14 = <0xff00>;
		ir_power_key_code15 = <0x14>;
		ir_addr_code15 = <0xff>;
		ir_power_key_code16 = <0x1d>;
		ir_addr_code16 = <0xfd02>;
		ir_power_key_code17 = <0x00>;
		ir_addr_code17 = <0xfe01>;
		ir_power_key_code18 = <0x02>;
		ir_addr_code18 = <0x707>;
		phandle = <0xbd>;
	};

	vdd-cpu {
		compatible = "sunxi-pwm-regulator";
		pwms = <0x61 0x01 0x1388 0x01>;
		regulator-name = "vdd_cpu";
		regulator-min-microvolt = <0xc5c10>;
		regulator-max-microvolt = <0x11b340>;
		regulator-ramp-delay = <0x19>;
		regulator-always-on;
		regulator-boot-on;
		status = "okay";
		phandle = <0x06>;
	};

	vdd-sys {
		compatible = "regulator-fixed";
		regulator-name = "vdd_sys";
		regulator-min-microvolt = <0xea600>;
		regulator-max-microvolt = <0xea600>;
		regulator-boot-on;
		regulator-always-on;
		phandle = <0x60>;
	};

	motor_ctr {
		compatible = "motor-control";
		motor-phase-num = <0x04>;
		motor-gpio-phase0 = <0x2c 0x07 0x04 0x00>;
		motor-gpio-phase1 = <0x2c 0x07 0x05 0x00>;
		motor-gpio-phase2 = <0x2c 0x07 0x06 0x00>;
		motor-gpio-phase3 = <0x2c 0x07 0x07 0x00>;
		limiter-up-gpio = <0x2c 0x07 0x0e 0x00>;
		active_level = <0x01>;
		motor_type = <0x01>;
		motor-step-num = <0x08>;
		motor-cycle = <0x03>;
		motor-step-type = <0x08>;
		motor-cw-table = <0x109080a 0x2060405>;
		motor-ccw-table = <0x5040602 0xa080901>;
		motor-phase-udelay = <0x01>;
		motor-step-mdelay = <0x04>;
		status = "okay";
		phandle = <0xbe>;
	};

	fan {
		compatible = "pwm-fan";
		status = "okay";
		#address-cells = <0x02>;
		#size-cells = <0x02>;
		reg = <0x00 0x2009800 0x00 0x400>;
		interrupts = <0x00 0x16 0x01>;
		clocks = <0x02 0x6a>;
		clock-names = "bus";
		resets = <0x02 0x35>;
		lradc-table = <0x12 0x41a 0x14 0x3f0 0x16 0x3b1 0x18 0x3db 0x1a 0x35c 0x1c 0x33e 0x1e 0x320 0x20 0x309 0x22 0x2e2 0x24 0x2be 0x26 0x2a0 0x28 0x28a 0x2a 0x271 0x2c 0x258 0x2e 0x24c 0x30 0x20d 0x32 0x1f8 0x34 0x1ef 0x36 0x1d6 0x38 0x1a5 0x3a 0x18f 0x3c 0x16f 0x3e 0x14f 0x40 0x13b 0x42 0x130 0x44 0x126 0x46 0x111 0x48 0xfc 0x4a 0xe7 0x4c 0xd2 0x4e 0xbc 0x50 0xaf>;
		gpadc-table = <0x00 0x5e6 0x05 0x5b4 0x14 0x4f8 0x15 0x4ea 0x16 0x4dc 0x17 0x4cd 0x18 0x4bf 0x19 0x4b0 0x1a 0x4a1 0x1b 0x492 0x1c 0x483 0x1d 0x474 0x1e 0x464 0x1f 0x455 0x20 0x446 0x21 0x437 0x22 0x427 0x23 0x418 0x24 0x408 0x25 0x3f9 0x26 0x3e9 0x27 0x3d9 0x28 0x3ca 0x29 0x3ba 0x2a 0x3ab 0x2b 0x39b 0x2c 0x38c 0x2d 0x37d 0x2e 0x36d 0x2f 0x35e 0x30 0x34f 0x31 0x340 0x32 0x331 0x33 0x323 0x34 0x314 0x35 0x306 0x36 0x2f8 0x37 0x2e9 0x38 0x2db 0x39 0x2cd 0x3a 0x2bf 0x3b 0x2b2 0x3c 0x2a4 0x3d 0x297 0x3e 0x28a 0x3f 0x27d 0x40 0x270 0x41 0x263 0x42 0x257 0x43 0x24a 0x44 0x23e 0x45 0x232 0x46 0x227 0x47 0x21b 0x48 0x210 0x49 0x204 0x4a 0x1f9 0x4b 0x1ee 0x4c 0x1e3 0x4d 0x1d9 0x4e 0x1cf 0x4f 0x1c5 0x50 0x1bb>;
		temp_poweroff = <0x3c>;
		temp_warn = <0x37>;
		pwm_ids = <0x00>;
		pwm_period_ns = <0x9c40>;
		default-duty = <0x32>;
		fan_policy = <0x01>;

		gpios {
			cam-usb-power-gpio = <0x18 0x00 0x03 0x00>;
			usb-power-gpio = <0x18 0x00 0x05 0x00>;
		};

		battery {
			enable = <0x00>;
			source = <0x01>;
			channel;
			bat-array = <0x508 0x53d 0x5a7 0x5d5 0x637>;
			bat_vol_off = <0x4da>;
			bat_vol_low = <0x4f1>;
			bat_vol_full = <0x601>;
			dc_in = <0x2c 0x01 0x05 0x00>;
			charge_ok = <0x2c 0x05 0x06 0x00>;
			power-hold = <0x18 0x00 0x03 0x00>;
		};

		switcher {
			enable = <0x00>;
			source = <0x00>;
			gpio-a = <0x2c 0x05 0x05 0x00>;
			gpio-b = <0x2c 0x05 0x04 0x00>;
		};

		ntc {
			ntc_num = <0x00>;

			ntc0 {
				enable = <0x01>;
				source = <0x01>;
				channel = <0x01>;
				fan_ids = <0x00>;
			};

			ntc1 {
				enable = <0x00>;
				source = <0x01>;
				channel = <0x01>;
				fan_ids = <0x00>;
			};
		};

		fan0 {
			temp-array = <0x1e 0x28 0x32 0x37 0x3c>;
			duty-array = <0x46 0x50 0x5a 0x5f 0x64>;
			duty-array-policy1 = <0x4b 0x4b 0x64 0x64>;
			fan-power-gpio = <0x2c 0x01 0x05 0x00>;
			fg-gpio = <0x2c 0x07 0x0d 0x00>;
			fg-warn-speed = <0x3e8>;
			fg-warn-cnt = <0x08>;
		};

		fan1 {
			temp-array = <0x1e 0x28 0x32 0x37 0x3c>;
			duty-array = <0x37 0x42 0x4d 0x5d 0x64>;
			duty-array-policy1 = <0x41 0x46 0x5a 0x64>;
		};
	};

	__symbols__ {
		tvsystem = "/reserved-memory/mipsloader";
		videoinfo = "/reserved-memory/decd";
		sharemem = "/reserved-memory/cpu_comm";
		framebuf = "/reserved-memory/framebuf";
		cpu0 = "/cpus/cpu@0";
		cpu1 = "/cpus/cpu@1";
		cpu2 = "/cpus/cpu@2";
		cpu3 = "/cpus/cpu@3";
		CPU_SLEEP_0 = "/cpus/idle-states/cpu-sleep-0";
		CLUSTER_SLEEP_0 = "/cpus/idle-states/cluster-sleep-0";
		dump_reg = "/dump-reg@100000";
		cpu_opp_table = "/cpu-opp-table";
		dcxo24M = "/dcxo24M_clk";
		gic = "/interrupt-controller@3020000";
		wakeupgen = "/interrupt-controller@0";
		mmu_aw = "/iommu@2010000";
		power = "/power-management@ff000000";
		pd = "/power-management@ff000000/power-controller";
		reg_pio1_8 = "/pio-18";
		reg_pio3_3 = "/pio-33";
		cpu_trips = "/thermal-zones/cpu_thermal_zone/trips";
		cpu_threshold = "/thermal-zones/cpu_thermal_zone/trips/trip-point@0";
		cpu_target = "/thermal-zones/cpu_thermal_zone/trips/trip-point@1";
		cpu_crit = "/thermal-zones/cpu_thermal_zone/trips/cpu_crit@0";
		soc = "/soc@2900000";
		sram_ctrl = "/soc@2900000/sram_ctrl@3000000";
		av1 = "/soc@2900000/av1@1c0d000";
		ve_opp_table = "/soc@2900000/opp_table";
		ve = "/soc@2900000/ve@1c0e000";
		ve1 = "/soc@2900000/ve1@1c0e000";
		pio = "/soc@2900000/pinctrl@2000000";
		nand0_pins_a = "/soc@2900000/pinctrl@2000000/nand0@0";
		nand0_pins_b = "/soc@2900000/pinctrl@2000000/nand0@1";
		nand0_pins_c = "/soc@2900000/pinctrl@2000000/nand0@2";
		sdc0_pins_a = "/soc@2900000/pinctrl@2000000/sdc0@0";
		sdc0_pins_b = "/soc@2900000/pinctrl@2000000/sdc0@1";
		sdc0_pins_c = "/soc@2900000/pinctrl@2000000/sdc0@2";
		sdc0_pins_d = "/soc@2900000/pinctrl@2000000/sdc0@3";
		sdc0_pins_e = "/soc@2900000/pinctrl@2000000/sdc0@4";
		sdc2_pins_a = "/soc@2900000/pinctrl@2000000/sdc2@0";
		sdc2_pins_b = "/soc@2900000/pinctrl@2000000/sdc2@1";
		sdc2_pins_c = "/soc@2900000/pinctrl@2000000/sdc2@2";
		sdc1_pins_a = "/soc@2900000/pinctrl@2000000/sdc1@0";
		sdc1_pins_b = "/soc@2900000/pinctrl@2000000/sdc1@1";
		uart0_pins_a = "/soc@2900000/pinctrl@2000000/uart0@0";
		uart0_pins_b = "/soc@2900000/pinctrl@2000000/uart0@1";
		uart1_pins_a = "/soc@2900000/pinctrl@2000000/uart1@0";
		uart1_pins_b = "/soc@2900000/pinctrl@2000000/uart1@1";
		twi2_pins_a = "/soc@2900000/pinctrl@2000000/twi2@0";
		twi2_pins_b = "/soc@2900000/pinctrl@2000000/twi2@1";
		twi1_pins_a = "/soc@2900000/pinctrl@2000000/twi1@0";
		twi1_pins_b = "/soc@2900000/pinctrl@2000000/twi1@1";
		gmac0_pins_a = "/soc@2900000/pinctrl@2000000/gmac@0";
		gmac0_pins_b = "/soc@2900000/pinctrl@2000000/gmac@1";
		pwm0_pin_a = "/soc@2900000/pinctrl@2000000/pwm0@0";
		pwm0_pin_c = "/soc@2900000/pinctrl@2000000/pwm0@2";
		pwm0_pin_b = "/soc@2900000/pinctrl@2000000/pwm0@1";
		pwm1_pin_a = "/soc@2900000/pinctrl@2000000/pwm1@0";
		pwm1_pin_b = "/soc@2900000/pinctrl@2000000/pwm1@1";
		pwm2_pin_a = "/soc@2900000/pinctrl@2000000/pwm2@0";
		pwm2_pin_b = "/soc@2900000/pinctrl@2000000/pwm2@1";
		pwm3_pin_a = "/soc@2900000/pinctrl@2000000/pwm3@0";
		pwm3_pin_b = "/soc@2900000/pinctrl@2000000/pwm3@1";
		pwm3_pin_c = "/soc@2900000/pinctrl@2000000/pwm3@2";
		pwm4_pin_a = "/soc@2900000/pinctrl@2000000/pwm4@0";
		pwm4_pin_b = "/soc@2900000/pinctrl@2000000/pwm4@1";
		spi1_pins_a = "/soc@2900000/pinctrl@2000000/spi1@0";
		spi1_pins_b = "/soc@2900000/pinctrl@2000000/spi1@1";
		spi1_pins_c = "/soc@2900000/pinctrl@2000000/spi1@2";
		mips_debug_pins_a = "/soc@2900000/pinctrl@2000000/mipsloader@0";
		mips_debug_pins_b = "/soc@2900000/pinctrl@2000000/mipsloader@1";
		mips_debug_pins_c = "/soc@2900000/pinctrl@2000000/mipsloader@2";
		owa_pins_a = "/soc@2900000/pinctrl@2000000/owa@0";
		owa_pins_b = "/soc@2900000/pinctrl@2000000/owa_sleep@0";
		daudio2_pins_a = "/soc@2900000/pinctrl@2000000/daudio2@0";
		daudio2_pins_b = "/soc@2900000/pinctrl@2000000/daudio2_sleep@0";
		ccu = "/soc@2900000/clock@2001000";
		audbrg = "/soc@2900000/audbrg@203042c";
		codec = "/soc@2900000/codec@2030000";
		dummy_cpudai = "/soc@2900000/dummy_cpudai@203032c";
		sndcodec = "/soc@2900000/sound@2030330";
		owa0 = "/soc@2900000/owa@2036000";
		soundowa0 = "/soc@2900000/soundowa0@203605c";
		owa1 = "/soc@2900000/owa@2037000";
		soundowa1 = "/soc@2900000/soundowa1@203705c";
		daudio0 = "/soc@2900000/daudio@2032000";
		sounddaudio0 = "/soc@2900000/sounddaudio0@203207c";
		daudio0_master = "/soc@2900000/sounddaudio0@203207c/simple-audio-card,codec";
		daudio1 = "/soc@2900000/daudio@2033000";
		sounddaudio1 = "/soc@2900000/sounddaudio0@203307c";
		daudio1_master = "/soc@2900000/sounddaudio0@203307c/simple-audio-card,codec";
		daudio2 = "/soc@2900000/daudio@2034000";
		sounddaudio2 = "/soc@2900000/sounddaudio2@203407c";
		daudio2_master = "/soc@2900000/sounddaudio2@203407c/simple-audio-card,codec";
		soc_timer0 = "/soc@2900000/timer@3060000";
		timer0 = "/soc@2900000/timer@0";
		timer1 = "/soc@2900000/timer@1";
		wdt0 = "/soc@2900000/watchdog@2051000";
		wdt1 = "/soc@2900000/watchdog@2051400";
		uart0 = "/soc@2900000/uart@2500000";
		uart1 = "/soc@2900000/uart@2500400";
		uart3 = "/soc@2900000/uart@2500c00";
		twi0 = "/soc@2900000/twi@2502000";
		twi1 = "/soc@2900000/twi@2502400";
		twi2 = "/soc@2900000/twi@2502800";
		twi3 = "/soc@2900000/twi@2502C00";
		r_twi0 = "/soc@2900000/r_twi@7081400";
		r_twi1 = "/soc@2900000/r_twi@7081800";
		dma = "/soc@2900000/dma-controller@3002000";
		msgbox = "/soc@2900000/msgbox@3003000";
		nmi_intc = "/soc@2900000/interrupt-controller@7010320";
		s_cir0 = "/soc@2900000/s_cir@7040000";
		ir_receiver = "/soc@2900000/ir_receiver";
		pwm = "/soc@2900000/pwm@2000c00";
		s_pwm = "/soc@2900000/s_pwm@7020c00";
		s_pwm0 = "/soc@2900000/s_pwm0@7020c10";
		s_pwm1 = "/soc@2900000/s_pwm1@7020c11";
		s_pwm2 = "/soc@2900000/s_pwm2@7004012";
		pwm0 = "/soc@2900000/pwm0@2000c10";
		pwm1 = "/soc@2900000/pwm1@2000c11";
		pwm2 = "/soc@2900000/pwm2@2000c12";
		pwm3 = "/soc@2900000/pwm3@2000c13";
		pwm4 = "/soc@2900000/pwm4@2000c14";
		pwm5 = "/soc@2900000/pwm5@2000c15";
		pwm6 = "/soc@2900000/pwm6@2000c16";
		pwm7 = "/soc@2900000/pwm7@2000c17";
		ac200 = "/soc@2900000/ac200@0";
		nsi0 = "/soc@2900000/nsi-controller@2020000";
		npd0 = "/soc@2900000/npd@02070000";
		vf_table = "/soc@2900000/sid@3006000/vf-table@00";
		ths_calib = "/soc@2900000/sid@3006000/calib@14";
		hwspinlock = "/soc@2900000/hwspinlock@3004000";
		sdc2 = "/soc@2900000/sdmmc@4022000";
		sdc0 = "/soc@2900000/sdmmc@4020000";
		sdc1 = "/soc@2900000/sdmmc@4021000";
		nand0 = "/soc@2900000/nand0@04011000";
		rtc_ccu = "/soc@2900000/rtc_ccu@7090000";
		rtc = "/soc@2900000/rtc@7090000";
		r_ccu = "/soc@2900000/clock@7010000";
		r_pio = "/soc@2900000/pinctrl@7022000";
		s_cir0_pins_a = "/soc@2900000/pinctrl@7022000/s_cir0@0";
		s_cir0_pins_b = "/soc@2900000/pinctrl@7022000/s_cir0@1";
		s_pwm0_pin_a = "/soc@2900000/pinctrl@7022000/s_pwm0@0";
		s_pwm0_pin_b = "/soc@2900000/pinctrl@7022000/s_pwm0@1";
		s_pwm1_pin_a = "/soc@2900000/pinctrl@7022000/s_pwm1@0";
		s_pwm1_pin_b = "/soc@2900000/pinctrl@7022000/s_pwm1@1";
		s_pwm2_pin_a = "/soc@2900000/pinctrl@7022000/s_pwm2@0";
		s_pwm2_pin_b = "/soc@2900000/pinctrl@7022000/s_pwm2@1";
		cryptoengine = "/soc@2900000/ce@03040000";
		ths = "/soc@2900000/ths@02009400";
		keyboard = "/soc@2900000/keyboard@2009800";
		gpadc = "/soc@2900000/gpadc@2009000";
		spi0 = "/soc@2900000/spi@4025000";
		spi1 = "/soc@2900000/spi@4026000";
		gmac0 = "/soc@2900000/eth@4500000";
		demux = "/soc@2900000/demux@6100000";
		cip = "/soc@2900000/cip@6000000";
		ci = "/soc@2900000/ci@6500000";
		ge2d = "/soc@2900000/ge2d@5240000";
		dtmb = "/soc@2900000/dtmb@6600000";
		dec = "/soc@2900000/dec@5600000";
		mipsloader = "/soc@2900000/dec@5600000/mipsloader@3061000";
		tvcap = "/soc@2900000/tvcap@6800000";
		tvdisp = "/soc@2900000/tvdisp@5000000";
		tvtop = "/soc@2900000/tvtop@5700000";
		tvtop_pm = "/soc@2900000/tvtop_pm@66666";
		usbc0 = "/soc@2900000/usbc0@0";
		udc = "/soc@2900000/udc-controller@4100000";
		ehci0 = "/soc@2900000/ehci0-controller@4101000";
		ohci0 = "/soc@2900000/ohci0-controller@4101400";
		usbc1 = "/soc@2900000/usbc1@0";
		ehci1 = "/soc@2900000/ehci1-controller@4200000";
		ohci1 = "/soc@2900000/ohci1-controller@4200400";
		usbc2 = "/soc@2900000/usbc2@0";
		ehci2 = "/soc@2900000/ehci2-controller@4300000";
		ohci2 = "/soc@2900000/ohci2-controller@4300400";
		rfkill = "/soc@2900000/rfkill";
		addr_mgt = "/soc@2900000/addr_mgt";
		btlpm = "/soc@2900000/btlpm";
		gpu = "/gpu@0x01800000";
		ipa_dvfs = "/gpu@0x01800000/ipa_dvfs";
		gpu_opp_table = "/gpu-opp-table";
		reg_usb1_vbus = "/usb1-vbus";
		arisc_config = "/arisc_config";
		standby_param = "/standby_param";
		virtual_ac_ps = "/virtual_ac_ps";
		cir_param = "/cir_param";
		reg_vdd_cpu = "/vdd-cpu";
		reg_vdd_sys = "/vdd-sys";
		motor_ctr = "/motor_ctr";
	};
};
